VERSION "Generated from CSV"

NS_ :

BS_:

BU_: CAN_IO CAR_PC EL_ECU PANTHER PUMA_FL PUMA_FR PUMA_R1 PUMA_R2 PUMA_RR1 SIMI
VAL_TABLE_ VT_SEAL_ActivationStatus 2 "deflate" 1 "inflate" 0 "ready" ;
VAL_TABLE_ VT_MON_State 1 "available" 0 "not available" ;
VAL_TABLE_ VT_HMI_SensorFusionRequest 1 "requested" 0 "not requested" ;
VAL_TABLE_ VT_ECU_PowerRequest 1 "Shutdown" 0 "Power On (default)" ;
VAL_TABLE_ VT_HMI_SEALActivationRequest 1 "request for inflate" 0 "request for exflate (default)" ;
VAL_TABLE_ VT_ELK_ResetErrorFlags 1 "reset error counters" 0 "nothing" ;
VAL_TABLE_ VT_ELK_LockingStatus 1 "locked" 0 "unlocked" ;
VAL_TABLE_ VT_ELK_LockingRequest 1 "Request for lock" 0 "No lock" ;
VAL_TABLE_ VT_ELK_ActuatorStatus 2 "Failure detected" 1 "Failure in previous cycle" 0 "No failure" ;
VAL_TABLE_ VT_BSW_BuckleState 1 "Buckled" 0 "Unbuckled" ;

BO_ 3221225472 VECTOR__INDEPENDENT_SIG_MSG: 0 Vector__XXX
 SG_ Generic_SeatFunctionEnable : 0|5@1+ (1,0) [0|31] "" Vector__XXX
 SG_ HB_State_FL : 0|8@1+ (1,0) [0|255] "" Vector__XXX

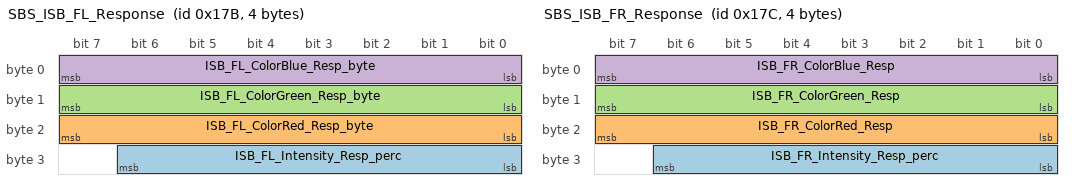
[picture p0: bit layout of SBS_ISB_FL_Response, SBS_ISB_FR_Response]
BO_ 379 SBS_ISB_FL_Response: 4 PUMA_FL
 SG_ ISB_FL_Intensity_Resp_perc : 24|7@1+ (1,0) [0|127] "" Vector__XXX
 SG_ ISB_FL_ColorRed_Resp_byte : 16|8@1+ (1,0) [0|255] "" Vector__XXX
 SG_ ISB_FL_ColorGreen_Resp_byte : 8|8@1+ (1,0) [0|255] "" Vector__XXX
 SG_ ISB_FL_ColorBlue_Resp_byte : 0|8@1+ (1,0) [0|255] "" Vector__XXX

BO_ 380 SBS_ISB_FR_Response: 4 PUMA_FR
 SG_ ISB_FR_Intensity_Resp_perc : 24|7@1+ (1,0) [0|127] "" Vector__XXX
 SG_ ISB_FR_ColorRed_Resp : 16|8@1+ (1,0) [0|255] "" Vector__XXX
 SG_ ISB_FR_ColorGreen_Resp : 8|8@1+ (1,0) [0|255] "" Vector__XXX
 SG_ ISB_FR_ColorBlue_Resp : 0|8@1+ (1,0) [0|255] "" Vector__XXX

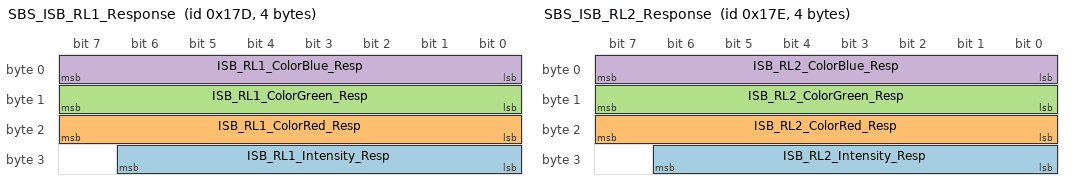
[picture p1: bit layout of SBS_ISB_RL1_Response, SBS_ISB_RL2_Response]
BO_ 381 SBS_ISB_RL1_Response: 4 PUMA_R1
 SG_ ISB_RL1_Intensity_Resp : 24|7@1+ (1,0) [0|127] "" Vector__XXX
 SG_ ISB_RL1_ColorRed_Resp : 16|8@1+ (1,0) [0|255] "" Vector__XXX
 SG_ ISB_RL1_ColorGreen_Resp : 8|8@1+ (1,0) [0|255] "" Vector__XXX
 SG_ ISB_RL1_ColorBlue_Resp : 0|8@1+ (1,0) [0|255] "" Vector__XXX

BO_ 382 SBS_ISB_RL2_Response: 4 PUMA_R2
 SG_ ISB_RL2_Intensity_Resp : 24|7@1+ (1,0) [0|127] "" Vector__XXX
 SG_ ISB_RL2_ColorRed_Resp : 16|8@1+ (1,0) [0|255] "" Vector__XXX
 SG_ ISB_RL2_ColorGreen_Resp : 8|8@1+ (1,0) [0|255] "" Vector__XXX
 SG_ ISB_RL2_ColorBlue_Resp : 0|8@1+ (1,0) [0|255] "" Vector__XXX

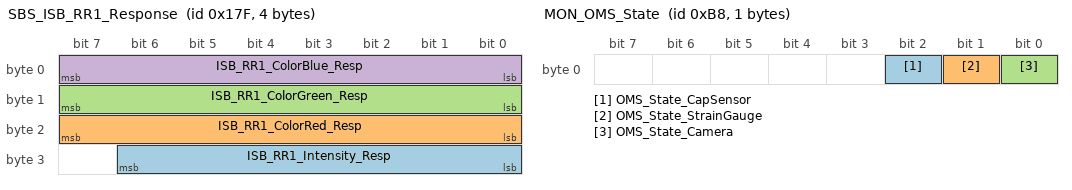
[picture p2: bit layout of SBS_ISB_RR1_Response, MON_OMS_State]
BO_ 383 SBS_ISB_RR1_Response: 4 PUMA_RR1
 SG_ ISB_RR1_Intensity_Resp : 24|7@1+ (1,0) [0|127] "" Vector__XXX
 SG_ ISB_RR1_ColorRed_Resp : 16|8@1+ (1,0) [0|255] "" Vector__XXX
 SG_ ISB_RR1_ColorGreen_Resp : 8|8@1+ (1,0) [0|255] "" Vector__XXX
 SG_ ISB_RR1_ColorBlue_Resp : 0|8@1+ (1,0) [0|255] "" Vector__XXX

BO_ 371 IRS_SEAL_RL2_Response: 1 PANTHER
 SG_ SEAL_RL2_ActivationStatus : 0|2@1+ (1,0) [0|3] "" Vector__XXX

BO_ 414 SBS_HB_RR1_Response: 4 PUMA_RR1
 SG_ HB_TargetTemp_RR1 : 24|8@1+ (0.5,-40) [-40|87.5] "" Vector__XXX
 SG_ HB_State_RR1 : 8|8@1+ (1,0) [0|255] "" Vector__XXX
 SG_ HB_ActualTemp_RR1 : 16|8@1+ (0.5,-40) [-40|87.5] "" Vector__XXX
 SG_ HB_PowerOut_RR1 : 0|8@1+ (1,0) [0|255] "" Vector__XXX

BO_ 413 SBS_HB_RL2_Response: 4 PUMA_R2
 SG_ HB_TargetTemp_RL2 : 24|8@1+ (0.5,-40) [-40|87.5] "" Vector__XXX
 SG_ HB_State_RL2 : 8|8@1+ (1,0) [0|255] "" Vector__XXX
 SG_ HB_ActualTemp_RL2 : 16|8@1+ (0.5,-40) [-40|87.5] "" Vector__XXX
 SG_ HB_PowerOut_RL2 : 0|8@1+ (1,0) [0|255] "" Vector__XXX

BO_ 412 SBS_HB_RL1_Response: 4 PUMA_R1
 SG_ HB_TargetTemp_RL1 : 24|8@1+ (0.5,-40) [-40|87.5] "" Vector__XXX
 SG_ HB_State_RL1 : 8|8@1+ (1,0) [0|255] "" Vector__XXX
 SG_ HB_ActualTemp_RL1 : 16|8@1+ (0.5,-40) [-40|87.5] "" Vector__XXX
 SG_ HB_PowerOut_RL1 : 0|8@1+ (1,0) [0|255] "" Vector__XXX

BO_ 184 MON_OMS_State: 1 SIMI
 SG_ OMS_State_CapSensor : 2|1@1+ (1,0) [0|1] "" Vector__XXX
 SG_ OMS_State_StrainGauge : 1|1@1+ (1,0) [0|1] "" Vector__XXX
 SG_ OMS_State_Camera : 0|1@1+ (1,0) [0|1] "" Vector__XXX

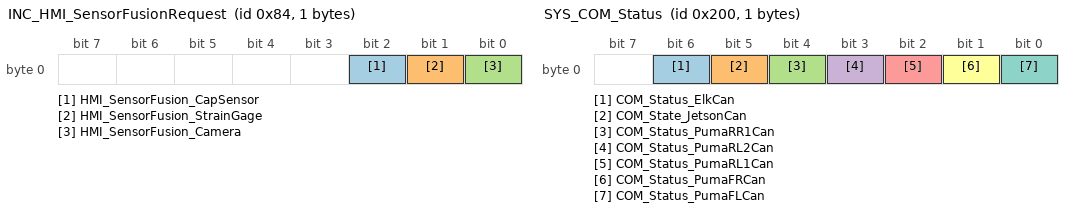
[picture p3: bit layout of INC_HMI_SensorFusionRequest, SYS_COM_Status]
BO_ 132 INC_HMI_SensorFusionRequest: 1 CAR_PC
 SG_ HMI_SensorFusion_CapSensor : 2|1@1+ (1,0) [0|1] "" Vector__XXX
 SG_ HMI_SensorFusion_StrainGage : 1|1@1+ (1,0) [0|1] "" Vector__XXX
 SG_ HMI_SensorFusion_Camera : 0|1@1+ (1,0) [0|1] "" Vector__XXX

BO_ 513 SYS_ECU_PowerRequest: 1 CAN_IO
 SG_ ECU_PowerRequest_Jetson : 0|1@1+ (1,0) [0|1] "" Vector__XXX

BO_ 512 SYS_COM_Status: 1 PANTHER
 SG_ COM_Status_ElkCan : 6|1@1+ (1,0) [0|1] "" Vector__XXX
 SG_ COM_State_JetsonCan : 5|1@1+ (1,0) [0|1] "" Vector__XXX
 SG_ COM_Status_PumaRR1Can : 4|1@1+ (1,0) [0|1] "" Vector__XXX
 SG_ COM_Status_PumaRL2Can : 3|1@1+ (1,0) [0|1] "" Vector__XXX
 SG_ COM_Status_PumaRL1Can : 2|1@1+ (1,0) [0|1] "" Vector__XXX
 SG_ COM_Status_PumaFRCan : 1|1@1+ (1,0) [0|1] "" Vector__XXX
 SG_ COM_Status_PumaFLCan : 0|1@1+ (1,0) [0|1] "" Vector__XXX

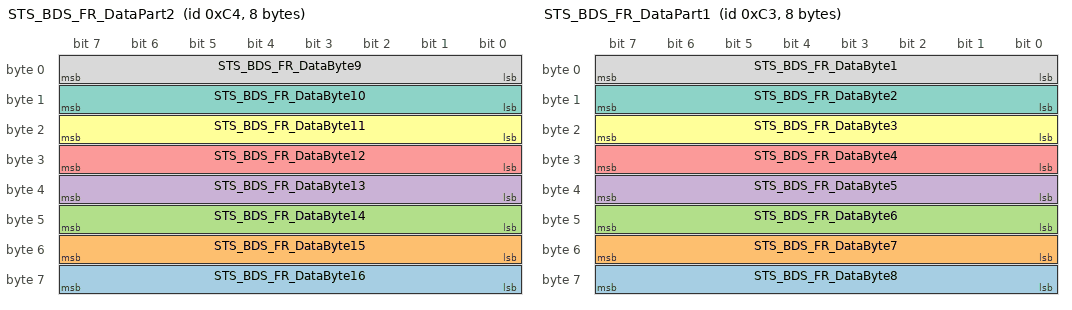
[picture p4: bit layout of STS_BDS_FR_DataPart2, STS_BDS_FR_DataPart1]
BO_ 196 STS_BDS_FR_DataPart2: 8 Vector__XXX
 SG_ STS_BDS_FR_DataByte16 : 56|8@1+ (1,0) [0|255] "" Vector__XXX
 SG_ STS_BDS_FR_DataByte15 : 48|8@1+ (1,0) [0|255] "" Vector__XXX
 SG_ STS_BDS_FR_DataByte14 : 40|8@1+ (1,0) [0|255] "" Vector__XXX
 SG_ STS_BDS_FR_DataByte13 : 32|8@1+ (1,0) [0|255] "" Vector__XXX
 SG_ STS_BDS_FR_DataByte12 : 24|8@1+ (1,0) [0|255] "" Vector__XXX
 SG_ STS_BDS_FR_DataByte11 : 16|8@1+ (1,0) [0|255] "" Vector__XXX
 SG_ STS_BDS_FR_DataByte10 : 8|8@1+ (1,0) [0|255] "" Vector__XXX
 SG_ STS_BDS_FR_DataByte9 : 0|8@1+ (1,0) [0|255] "" Vector__XXX

BO_ 195 STS_BDS_FR_DataPart1: 8 Vector__XXX
 SG_ STS_BDS_FR_DataByte8 : 56|8@1+ (1,0) [0|255] "" Vector__XXX
 SG_ STS_BDS_FR_DataByte7 : 48|8@1+ (1,0) [0|255] "" Vector__XXX
 SG_ STS_BDS_FR_DataByte6 : 40|8@1+ (1,0) [0|255] "" Vector__XXX
 SG_ STS_BDS_FR_DataByte5 : 32|8@1+ (1,0) [0|255] "" Vector__XXX
 SG_ STS_BDS_FR_DataByte4 : 24|8@1+ (1,0) [0|255] "" Vector__XXX
 SG_ STS_BDS_FR_DataByte3 : 16|8@1+ (1,0) [0|255] "" Vector__XXX
 SG_ STS_BDS_FR_DataByte2 : 8|8@1+ (1,0) [0|255] "" Vector__XXX
 SG_ STS_BDS_FR_DataByte1 : 0|8@1+ (1,0) [0|255] "" Vector__XXX

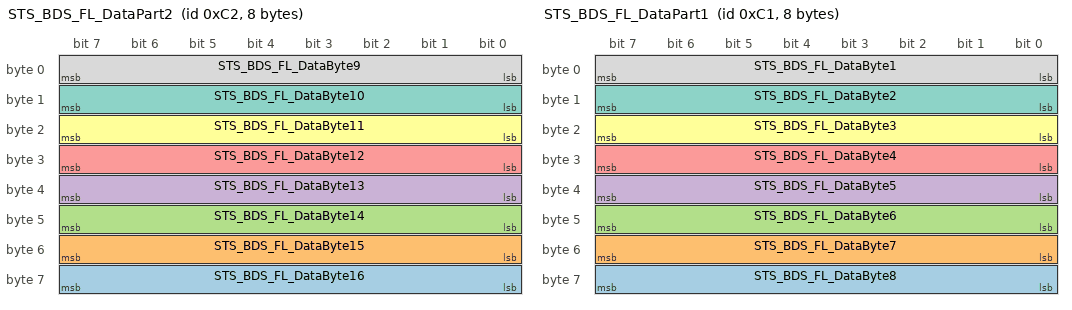
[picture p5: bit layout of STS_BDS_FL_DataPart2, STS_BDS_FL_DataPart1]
BO_ 194 STS_BDS_FL_DataPart2: 8 Vector__XXX
 SG_ STS_BDS_FL_DataByte16 : 56|8@1+ (1,0) [0|255] "" Vector__XXX
 SG_ STS_BDS_FL_DataByte15 : 48|8@1+ (1,0) [0|255] "" Vector__XXX
 SG_ STS_BDS_FL_DataByte14 : 40|8@1+ (1,0) [0|255] "" Vector__XXX
 SG_ STS_BDS_FL_DataByte13 : 32|8@1+ (1,0) [0|255] "" Vector__XXX
 SG_ STS_BDS_FL_DataByte12 : 24|8@1+ (1,0) [0|255] "" Vector__XXX
 SG_ STS_BDS_FL_DataByte11 : 16|8@1+ (1,0) [0|255] "" Vector__XXX
 SG_ STS_BDS_FL_DataByte10 : 8|8@1+ (1,0) [0|255] "" Vector__XXX
 SG_ STS_BDS_FL_DataByte9 : 0|8@1+ (1,0) [0|255] "" Vector__XXX

BO_ 193 STS_BDS_FL_DataPart1: 8 Vector__XXX
 SG_ STS_BDS_FL_DataByte8 : 56|8@1+ (1,0) [0|255] "" Vector__XXX
 SG_ STS_BDS_FL_DataByte7 : 48|8@1+ (1,0) [0|255] "" Vector__XXX
 SG_ STS_BDS_FL_DataByte6 : 40|8@1+ (1,0) [0|255] "" Vector__XXX
 SG_ STS_BDS_FL_DataByte5 : 32|8@1+ (1,0) [0|255] "" Vector__XXX
 SG_ STS_BDS_FL_DataByte4 : 24|8@1+ (1,0) [0|255] "" Vector__XXX
 SG_ STS_BDS_FL_DataByte3 : 16|8@1+ (1,0) [0|255] "" Vector__XXX
 SG_ STS_BDS_FL_DataByte2 : 8|8@1+ (1,0) [0|255] "" Vector__XXX
 SG_ STS_BDS_FL_DataByte1 : 0|8@1+ (1,0) [0|255] "" Vector__XXX

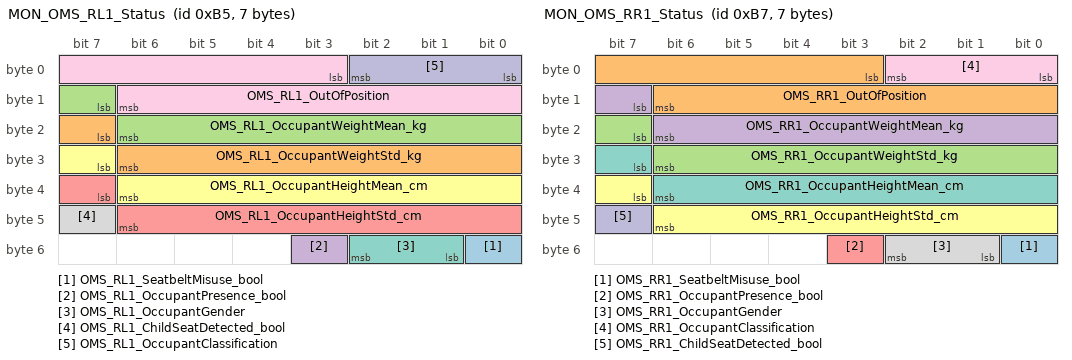
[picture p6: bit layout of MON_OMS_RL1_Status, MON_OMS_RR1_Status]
BO_ 181 MON_OMS_RL1_Status: 7 Vector__XXX
 SG_ OMS_RL1_SeatbeltMisuse_bool : 48|1@1+ (1,0) [0|1] "" Vector__XXX
 SG_ OMS_RL1_OccupantWeightStd_kg : 23|8@1+ (1,0) [0|255] "" Vector__XXX
 SG_ OMS_RL1_OccupantWeightMean_kg : 15|8@1+ (1,0) [0|255] "" Vector__XXX
 SG_ OMS_RL1_OccupantPresence_bool : 51|1@1+ (1,0) [0|1] "" Vector__XXX
 SG_ OMS_RL1_OccupantHeightStd_cm : 39|8@1+ (1,0) [0|255] "" Vector__XXX
 SG_ OMS_RL1_OccupantHeightMean_cm : 31|8@1+ (1,0) [0|255] "" Vector__XXX
 SG_ OMS_RL1_OccupantGender : 49|2@1+ (1,0) [0|3] "" Vector__XXX
 SG_ OMS_RL1_ChildSeatDetected_bool : 47|1@1+ (1,0) [0|1] "" Vector__XXX
 SG_ OMS_RL1_OutOfPosition : 3|12@1+ (1,0) [0|4095] "" Vector__XXX
 SG_ OMS_RL1_OccupantClassification : 0|3@1+ (1,0) [0|7] "" Vector__XXX

BO_ 183 MON_OMS_RR1_Status: 7 Vector__XXX
 SG_ OMS_RR1_SeatbeltMisuse_bool : 48|1@1+ (1,0) [0|1] "" Vector__XXX
 SG_ OMS_RR1_OutOfPosition : 3|12@1+ (1,0) [0|4095] "" Vector__XXX
 SG_ OMS_RR1_OccupantWeightStd_kg : 23|8@1+ (1,0) [0|255] "" Vector__XXX
 SG_ OMS_RR1_OccupantWeightMean_kg : 15|8@1+ (1,0) [0|255] "" Vector__XXX
 SG_ OMS_RR1_OccupantPresence_bool : 51|1@1+ (1,0) [0|1] "" Vector__XXX
 SG_ OMS_RR1_OccupantHeightStd_cm : 39|8@1+ (1,0) [0|255] "" Vector__XXX
 SG_ OMS_RR1_OccupantHeightMean_cm : 31|8@1+ (1,0) [0|255] "" Vector__XXX
 SG_ OMS_RR1_OccupantGender : 49|2@1+ (1,0) [0|3] "" Vector__XXX
 SG_ OMS_RR1_OccupantClassification : 0|3@1+ (1,0) [0|7] "" Vector__XXX
 SG_ OMS_RR1_ChildSeatDetected_bool : 47|1@1+ (1,0) [0|1] "" Vector__XXX

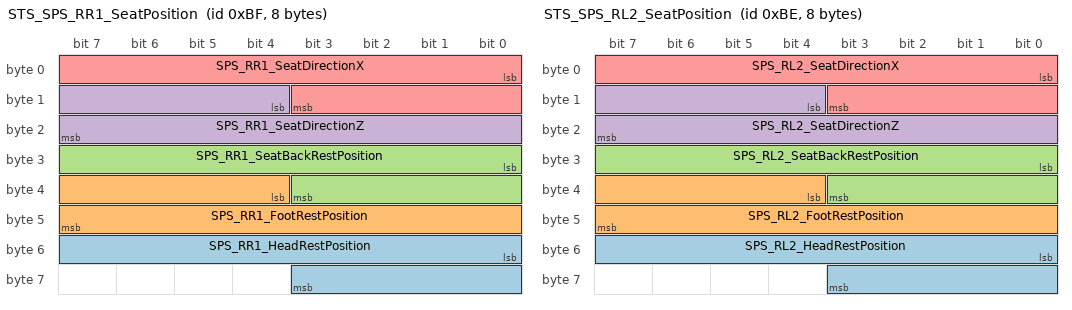
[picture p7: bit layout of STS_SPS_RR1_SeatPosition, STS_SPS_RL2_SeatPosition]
BO_ 191 STS_SPS_RR1_SeatPosition: 8 Vector__XXX
 SG_ SPS_RR1_HeadRestPosition : 48|12@1+ (1,0) [0|4095] "" Vector__XXX
 SG_ SPS_RR1_FootRestPosition : 36|12@1+ (1,0) [0|4095] "" Vector__XXX
 SG_ SPS_RR1_SeatBackRestPosition : 24|12@1+ (1,0) [0|4095] "" Vector__XXX
 SG_ SPS_RR1_SeatDirectionZ : 12|12@1+ (1,0) [0|4095] "" Vector__XXX
 SG_ SPS_RR1_SeatDirectionX : 0|12@1+ (1,0) [0|4095] "" Vector__XXX

BO_ 190 STS_SPS_RL2_SeatPosition: 8 Vector__XXX
 SG_ SPS_RL2_HeadRestPosition : 48|12@1+ (1,0) [0|4095] "" Vector__XXX
 SG_ SPS_RL2_FootRestPosition : 36|12@1+ (1,0) [0|4095] "" Vector__XXX
 SG_ SPS_RL2_SeatBackRestPosition : 24|12@1+ (1,0) [0|4095] "" Vector__XXX
 SG_ SPS_RL2_SeatDirectionZ : 12|12@1+ (1,0) [0|4095] "" Vector__XXX
 SG_ SPS_RL2_SeatDirectionX : 0|12@1+ (1,0) [0|4095] "" Vector__XXX

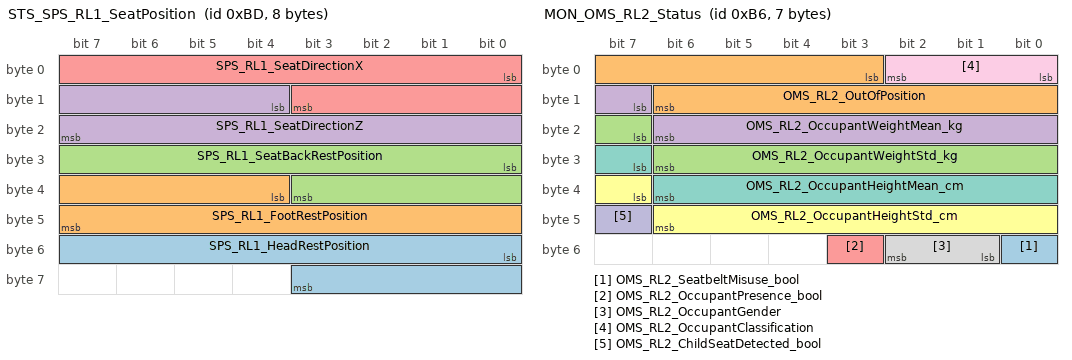
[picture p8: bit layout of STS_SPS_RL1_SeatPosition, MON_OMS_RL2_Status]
BO_ 189 STS_SPS_RL1_SeatPosition: 8 Vector__XXX
 SG_ SPS_RL1_HeadRestPosition : 48|12@1+ (1,0) [0|4095] "" Vector__XXX
 SG_ SPS_RL1_FootRestPosition : 36|12@1+ (1,0) [0|4095] "" Vector__XXX
 SG_ SPS_RL1_SeatBackRestPosition : 24|12@1+ (1,0) [0|4095] "" Vector__XXX
 SG_ SPS_RL1_SeatDirectionZ : 12|12@1+ (1,0) [0|4095] "" Vector__XXX
 SG_ SPS_RL1_SeatDirectionX : 0|12@1+ (1,0) [0|4095] "" Vector__XXX

BO_ 182 MON_OMS_RL2_Status: 7 Vector__XXX
 SG_ OMS_RL2_SeatbeltMisuse_bool : 48|1@1+ (1,0) [0|1] "" Vector__XXX
 SG_ OMS_RL2_OutOfPosition : 3|12@1+ (1,0) [0|4095] "" Vector__XXX
 SG_ OMS_RL2_OccupantWeightStd_kg : 23|8@1+ (1,0) [0|255] "" Vector__XXX
 SG_ OMS_RL2_OccupantWeightMean_kg : 15|8@1+ (1,0) [0|255] "" Vector__XXX
 SG_ OMS_RL2_OccupantPresence_bool : 51|1@1+ (1,0) [0|1] "" Vector__XXX
 SG_ OMS_RL2_OccupantHeightStd_cm : 39|8@1+ (1,0) [0|255] "" Vector__XXX
 SG_ OMS_RL2_OccupantHeightMean_cm : 31|8@1+ (1,0) [0|255] "" Vector__XXX
 SG_ OMS_RL2_OccupantGender : 49|2@1+ (1,0) [0|3] "" Vector__XXX
 SG_ OMS_RL2_OccupantClassification : 0|3@1+ (1,0) [0|7] "" Vector__XXX
 SG_ OMS_RL2_ChildSeatDetected_bool : 47|1@1+ (1,0) [0|1] "" Vector__XXX

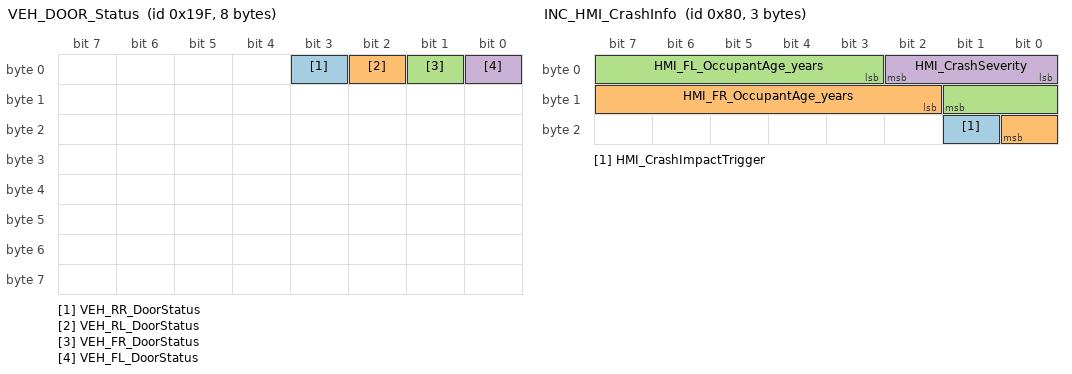
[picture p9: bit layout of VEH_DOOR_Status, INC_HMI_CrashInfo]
BO_ 415 VEH_DOOR_Status: 8 Vector__XXX
 SG_ VEH_RR_DoorStatus : 3|1@1+ (1,0) [0|1] "" Vector__XXX
 SG_ VEH_RL_DoorStatus : 2|1@1+ (1,0) [0|1] "" Vector__XXX
 SG_ VEH_FR_DoorStatus : 1|1@1+ (1,0) [0|1] "" Vector__XXX
 SG_ VEH_FL_DoorStatus : 0|1@1+ (1,0) [0|1] "" Vector__XXX

BO_ 128 INC_HMI_CrashInfo: 3 CAR_PC
 SG_ HMI_CrashImpactTrigger : 17|1@1+ (1,0) [0|1] ""  PANTHER
 SG_ HMI_FR_OccupantAge_years : 10|7@1+ (1,0) [0|127] ""  PANTHER
 SG_ HMI_FL_OccupantAge_years : 3|7@1+ (1,0) [0|127] ""  PANTHER
 SG_ HMI_CrashSeverity : 0|3@1+ (1,0) [0|7] ""  PANTHER

BO_ 129 INC_HMI_SEALRequest: 1 CAR_PC
 SG_ HMI_SEAL_ActivationRequest : 0|2@1+ (1,0) [0|3] ""  PANTHER

BO_ 177 MON_ARS_InjuryRisk: 4 PANTHER
 SG_ ARS_FR_InjuryRiskNonAdaptive : 24|8@1+ (1,0) [0|255] ""  CAR_PC
 SG_ ARS_FR_InjuryRiskAdaptive : 16|8@1+ (1,0) [0|255] ""  CAR_PC
 SG_ ARS_FL_InjuryRiskNonAdaptive : 8|8@1+ (1,0) [0|255] ""  CAR_PC
 SG_ ARS_FL_InjuryRiskAdaptive : 0|8@1+ (1,0) [0|255] ""  CAR_PC

BO_ 130 MON_ARS_MSLLRequest: 1 PANTHER
 SG_ ARS_MSLL_ActivationRequest : 0|8@1+ (1,0) [0|255] ""  CAR_PC

BO_ 178 MON_ARS_TTF: 4 PANTHER
 SG_ ARS_FR_TimeToFireSeatbelt : 24|8@1+ (1,0) [0|255] ""  CAR_PC
 SG_ ARS_FR_TimeToFireAirbag : 16|8@1+ (1,0) [0|255] ""  CAR_PC
 SG_ ARS_FL_TimeToFireSeatbelt : 8|8@1+ (1,0) [0|255] ""  CAR_PC
 SG_ ARS_FL_TimeToFireAirbag : 0|8@1+ (1,0) [0|255] ""  CAR_PC

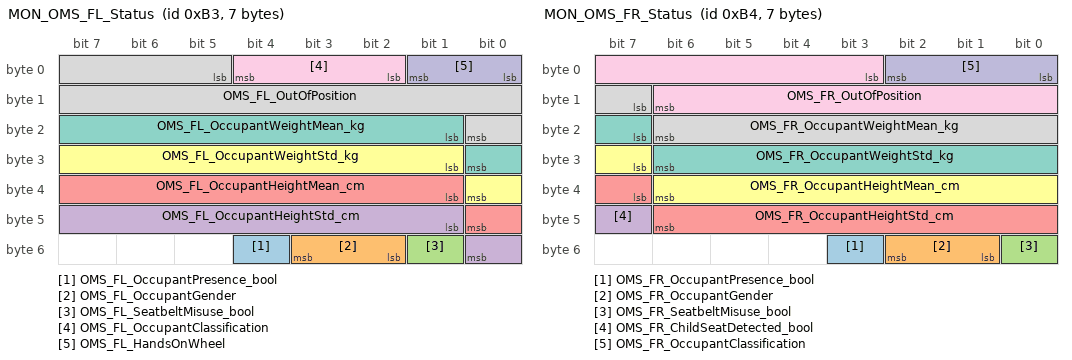
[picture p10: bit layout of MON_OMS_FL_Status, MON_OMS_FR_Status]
BO_ 179 MON_OMS_FL_Status: 7 PANTHER
 SG_ OMS_FL_OccupantPresence_bool : 52|1@1+ (1,0) [0|1] "" Vector__XXX
 SG_ OMS_FL_OccupantGender : 50|2@1+ (1,0) [0|3] ""  CAR_PC,PANTHER
 SG_ OMS_FL_SeatbeltMisuse_bool : 49|1@1+ (1,0) [0|1] ""  CAR_PC,PANTHER
 SG_ OMS_FL_OccupantHeightStd_cm : 41|8@1+ (1,0) [0|255] ""  CAR_PC,PANTHER
 SG_ OMS_FL_OccupantHeightMean_cm : 33|8@1+ (1,0) [0|255] ""  CAR_PC,PANTHER
 SG_ OMS_FL_OccupantWeightStd_kg : 25|8@1+ (1,0) [0|255] ""  CAR_PC,PANTHER
 SG_ OMS_FL_OccupantWeightMean_kg : 17|8@1+ (1,0) [0|255] ""  CAR_PC,PANTHER
 SG_ OMS_FL_OutOfPosition : 5|12@1+ (1,0) [0|4095] ""  PANTHER
 SG_ OMS_FL_OccupantClassification : 2|3@1+ (1,0) [0|7] ""  CAR_PC,PANTHER
 SG_ OMS_FL_HandsOnWheel : 0|2@1+ (1,0) [0|3] ""  CAR_PC,PANTHER

BO_ 180 MON_OMS_FR_Status: 7 PANTHER
 SG_ OMS_FR_OccupantPresence_bool : 51|1@1+ (1,0) [0|1] "" Vector__XXX
 SG_ OMS_FR_OccupantGender : 49|2@1+ (1,0) [0|3] ""  CAR_PC,PANTHER
 SG_ OMS_FR_SeatbeltMisuse_bool : 48|1@1+ (1,0) [0|1] ""  CAR_PC,PANTHER
 SG_ OMS_FR_ChildSeatDetected_bool : 47|1@1+ (1,0) [0|1] ""  CAR_PC,PANTHER
 SG_ OMS_FR_OccupantHeightStd_cm : 39|8@1+ (1,0) [0|255] ""  CAR_PC,PANTHER
 SG_ OMS_FR_OccupantHeightMean_cm : 31|8@1+ (1,0) [0|255] ""  CAR_PC,PANTHER
 SG_ OMS_FR_OccupantWeightStd_kg : 23|8@1+ (1,0) [0|255] ""  CAR_PC,PANTHER
 SG_ OMS_FR_OccupantWeightMean_kg : 15|8@1+ (1,0) [0|255] ""  CAR_PC,PANTHER
 SG_ OMS_FR_OutOfPosition : 3|12@1+ (1,0) [0|4095] ""  PANTHER
 SG_ OMS_FR_OccupantClassification : 0|3@1+ (1,0) [0|7] ""  CAR_PC,PANTHER

BO_ 176 MON_SMA_VehicleState: 1 PANTHER
 SG_ SMA_VehicleStable : 0|1@1+ (1,0) [0|1] ""  CAR_PC

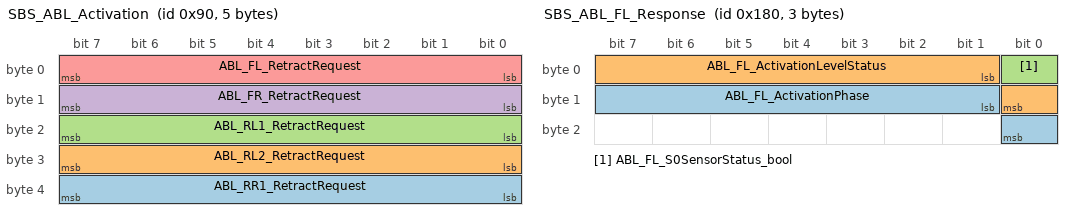
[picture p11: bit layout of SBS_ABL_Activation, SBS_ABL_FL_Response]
BO_ 144 SBS_ABL_Activation: 5 PANTHER
 SG_ ABL_RR1_RetractRequest : 32|8@1+ (1,0) [0|255] ""  PANTHER,PUMA_RR1
 SG_ ABL_RL2_RetractRequest : 24|8@1+ (1,0) [0|255] ""  PANTHER,PUMA_R2
 SG_ ABL_RL1_RetractRequest : 16|8@1+ (1,0) [0|255] ""  PANTHER,PUMA_R1
 SG_ ABL_FR_RetractRequest : 8|8@1+ (1,0) [0|255] ""  PANTHER,PUMA_FR
 SG_ ABL_FL_RetractRequest : 0|8@1+ (1,0) [0|255] ""  PANTHER,PUMA_FL

BO_ 384 SBS_ABL_FL_Response: 3 PUMA_FL
 SG_ ABL_FL_ActivationPhase : 9|8@1+ (1,0) [0|255] ""  PANTHER
 SG_ ABL_FL_ActivationLevelStatus : 1|8@1+ (1,0) [0|255] ""  PANTHER
 SG_ ABL_FL_S0SensorStatus_bool : 0|1@1+ (1,0) [0|1] ""  PANTHER

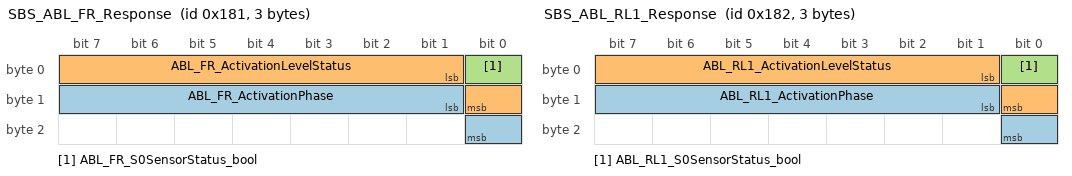
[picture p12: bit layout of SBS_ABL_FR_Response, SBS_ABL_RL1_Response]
BO_ 385 SBS_ABL_FR_Response: 3 PUMA_FR
 SG_ ABL_FR_ActivationPhase : 9|8@1+ (1,0) [0|255] ""  PANTHER
 SG_ ABL_FR_ActivationLevelStatus : 1|8@1+ (1,0) [0|255] ""  PANTHER
 SG_ ABL_FR_S0SensorStatus_bool : 0|1@1+ (1,0) [0|1] ""  PANTHER

BO_ 386 SBS_ABL_RL1_Response: 3 PUMA_R1
 SG_ ABL_RL1_ActivationPhase : 9|8@1+ (1,0) [0|255] ""  PANTHER
 SG_ ABL_RL1_ActivationLevelStatus : 1|8@1+ (1,0) [0|255] ""  PANTHER
 SG_ ABL_RL1_S0SensorStatus_bool : 0|1@1+ (1,0) [0|1] ""  PANTHER

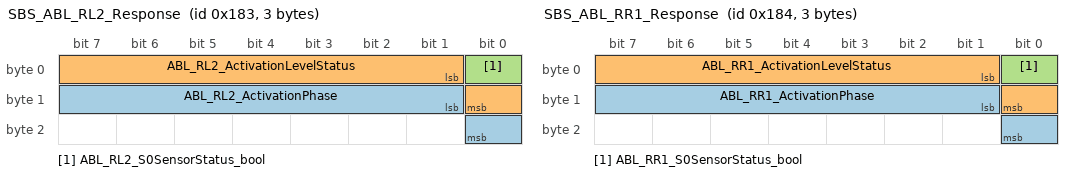
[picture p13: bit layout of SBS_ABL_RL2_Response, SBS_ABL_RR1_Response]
BO_ 387 SBS_ABL_RL2_Response: 3 PUMA_R2
 SG_ ABL_RL2_ActivationPhase : 9|8@1+ (1,0) [0|255] ""  PANTHER
 SG_ ABL_RL2_ActivationLevelStatus : 1|8@1+ (1,0) [0|255] ""  PANTHER
 SG_ ABL_RL2_S0SensorStatus_bool : 0|1@1+ (1,0) [0|1] ""  PANTHER

BO_ 388 SBS_ABL_RR1_Response: 3 PUMA_RR1
 SG_ ABL_RR1_ActivationPhase : 9|8@1+ (1,0) [0|255] ""  PANTHER
 SG_ ABL_RR1_ActivationLevelStatus : 1|8@1+ (1,0) [0|255] ""  PANTHER
 SG_ ABL_RR1_S0SensorStatus_bool : 0|1@1+ (1,0) [0|1] ""  PANTHER

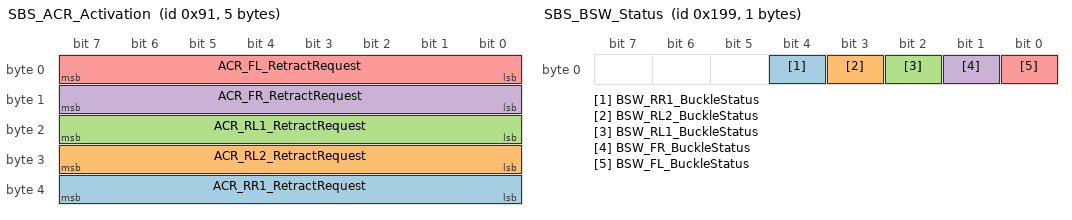
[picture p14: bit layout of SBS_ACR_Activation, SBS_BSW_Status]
BO_ 145 SBS_ACR_Activation: 5 PANTHER
 SG_ ACR_RR1_RetractRequest : 32|8@1+ (1,0) [0|255] ""  PANTHER,PUMA_RR1
 SG_ ACR_RL2_RetractRequest : 24|8@1+ (1,0) [0|255] ""  PANTHER,PUMA_R2
 SG_ ACR_RL1_RetractRequest : 16|8@1+ (1,0) [0|255] ""  PANTHER,PUMA_R1
 SG_ ACR_FR_RetractRequest : 8|8@1+ (1,0) [0|255] ""  PANTHER,PUMA_FR
 SG_ ACR_FL_RetractRequest : 0|8@1+ (1,0) [0|255] ""  PANTHER,PUMA_FL

BO_ 392 SBS_ACR_FL_Response: 3 PUMA_FL
 SG_ ACR_FL_SpoolFasterClutch : 16|8@1+ (1,0) [0|255] ""  PANTHER
 SG_ ACR_FL_ActivationPhase : 8|8@1+ (1,0) [0|255] ""  PANTHER
 SG_ ACR_FL_ActivationLevelStatus : 0|8@1+ (1,0) [0|255] ""  PANTHER

BO_ 393 SBS_ACR_FR_Response: 3 PUMA_FR
 SG_ ACR_FR_SpoolFasterClutch : 16|8@1+ (1,0) [0|255] ""  PANTHER
 SG_ ACR_FR_ActivationPhase : 8|8@1+ (1,0) [0|255] ""  PANTHER
 SG_ ACR_FR_ActivationLevelStatus : 0|8@1+ (1,0) [0|255] ""  PANTHER

BO_ 394 SBS_ACR_RL1_Response: 3 PUMA_R1
 SG_ ACR_RL1_SpoolFasterClutch : 16|8@1+ (1,0) [0|255] ""  PANTHER
 SG_ ACR_RL1_ActivationPhase : 8|8@1+ (1,0) [0|255] ""  PANTHER
 SG_ ACR_RL1_ActivationLevelStatus : 0|8@1+ (1,0) [0|255] ""  PANTHER

BO_ 395 SBS_ACR_RL2_Response: 3 PUMA_R2
 SG_ ACR_RL2_SpoolFasterClutch : 16|8@1+ (1,0) [0|255] ""  PANTHER
 SG_ ACR_RL2_ActivationPhase : 8|8@1+ (1,0) [0|255] ""  PANTHER
 SG_ ACR_RL2_ActivationLevelStatus : 0|8@1+ (1,0) [0|255] ""  PANTHER

BO_ 396 SBS_ACR_RR1_Response: 3 PUMA_RR1
 SG_ ACR_RR1_SpoolFasterClutch : 16|8@1+ (1,0) [0|255] ""  PANTHER
 SG_ ACR_RR1_ActivationPhase : 8|8@1+ (1,0) [0|255] ""  PANTHER
 SG_ ACR_RR1_ActivationLevelStatus : 0|8@1+ (1,0) [0|255] ""  PANTHER

BO_ 409 SBS_BSW_Status: 1 PANTHER
 SG_ BSW_RR1_BuckleStatus : 4|1@1+ (1,0) [0|1] ""  CAR_PC
 SG_ BSW_RL2_BuckleStatus : 3|1@1+ (1,0) [0|1] ""  CAR_PC
 SG_ BSW_RL1_BuckleStatus : 2|1@1+ (1,0) [0|1] ""  CAR_PC
 SG_ BSW_FR_BuckleStatus : 1|1@1+ (1,0) [0|1] ""  CAR_PC
 SG_ BSW_FL_BuckleStatus : 0|1@1+ (1,0) [0|1] ""  CAR_PC

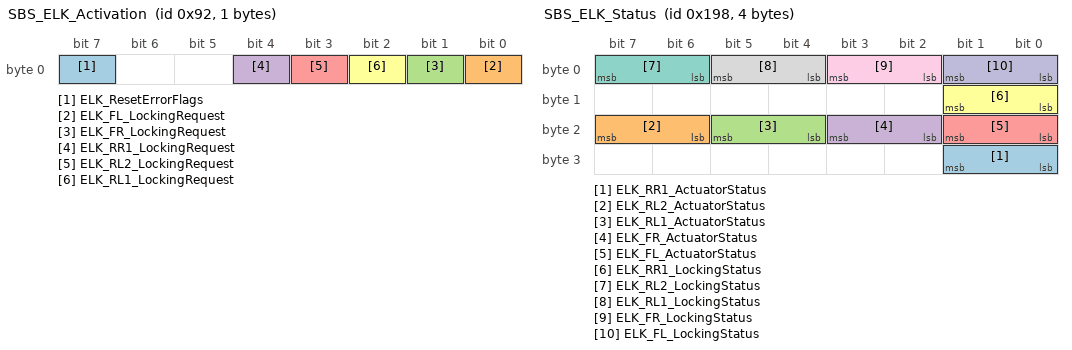
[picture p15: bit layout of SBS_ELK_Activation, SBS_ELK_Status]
BO_ 146 SBS_ELK_Activation: 1 PANTHER
 SG_ ELK_ResetErrorFlags : 7|1@1+ (1,0) [0|1] "" Vector__XXX
 SG_ ELK_FL_LockingRequest : 0|1@1+ (1,0) [0|1] ""  EL_ECU,PANTHER
 SG_ ELK_FR_LockingRequest : 1|1@1+ (1,0) [0|1] ""  EL_ECU,PANTHER
 SG_ ELK_RR1_LockingRequest : 4|1@1+ (1,0) [0|1] ""  PANTHER,EL_ECU
 SG_ ELK_RL2_LockingRequest : 3|1@1+ (1,0) [0|1] ""  PANTHER,EL_ECU
 SG_ ELK_RL1_LockingRequest : 2|1@1+ (1,0) [0|1] ""  PANTHER,EL_ECU

BO_ 408 SBS_ELK_Status: 4 PANTHER
 SG_ ELK_RR1_ActuatorStatus : 24|2@1+ (1,0) [0|3] "" Vector__XXX
 SG_ ELK_RL2_ActuatorStatus : 22|2@1+ (1,0) [0|3] "" Vector__XXX
 SG_ ELK_RL1_ActuatorStatus : 20|2@1+ (1,0) [0|3] "" Vector__XXX
 SG_ ELK_FR_ActuatorStatus : 18|2@1+ (1,0) [0|3] "" Vector__XXX
 SG_ ELK_FL_ActuatorStatus : 16|2@1+ (1,0) [0|3] "" Vector__XXX
 SG_ ELK_RR1_LockingStatus : 8|2@1+ (1,0) [0|3] ""  CAR_PC,PANTHER
 SG_ ELK_RL2_LockingStatus : 6|2@1+ (1,0) [0|3] ""  CAR_PC,PANTHER
 SG_ ELK_RL1_LockingStatus : 4|2@1+ (1,0) [0|3] ""  CAR_PC,PANTHER
 SG_ ELK_FR_LockingStatus : 2|2@1+ (1,0) [0|3] ""  CAR_PC,PANTHER
 SG_ ELK_FL_LockingStatus : 0|2@1+ (1,0) [0|3] ""  CAR_PC,PANTHER

BO_ 411 SBS_HB_FR_Response: 4 PUMA_FR
 SG_ HB_TargetTemp_FR : 16|8@1+ (0.5,-40) [-40|87.5] "" Vector__XXX
 SG_ HB_State_FR : 24|8@1+ (1,0) [0|255] "" Vector__XXX
 SG_ HB_ActualTemp_FR : 8|8@1+ (0.5,-40) [-40|87.5] "" Vector__XXX
 SG_ HB_PowerOut_FR : 0|8@1+ (1,0) [0|255] "" Vector__XXX

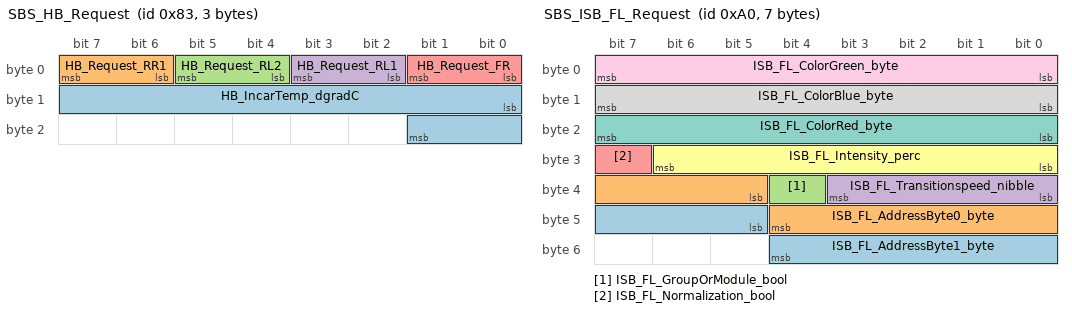
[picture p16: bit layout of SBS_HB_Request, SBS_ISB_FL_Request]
BO_ 131 SBS_HB_Request: 3 PANTHER
 SG_ HB_IncarTemp_dgradC : 8|10@1- (1,0) [-512|511] "" Vector__XXX
 SG_ HB_Request_RR1 : 6|2@1+ (1,0) [0|3] "" Vector__XXX
 SG_ HB_Request_RL2 : 4|2@1+ (1,0) [0|3] "" Vector__XXX
 SG_ HB_Request_RL1 : 2|2@1+ (1,0) [0|3] "" Vector__XXX
 SG_ HB_Request_FR : 0|2@1+ (1,0) [0|3] "" Vector__XXX

BO_ 160 SBS_ISB_FL_Request: 7 PANTHER
 SG_ ISB_FL_AddressByte1_byte : 45|8@1+ (1,0) [0|255] ""  PANTHER,PUMA_FL
 SG_ ISB_FL_AddressByte0_byte : 37|8@1+ (1,0) [0|255] ""  PANTHER,PUMA_FL
 SG_ ISB_FL_GroupOrModule_bool : 36|1@1+ (1,0) [0|1] ""  PANTHER,PUMA_FL
 SG_ ISB_FL_Transitionspeed_nibble : 32|4@1+ (1,0) [0|15] ""  PANTHER,PUMA_FL
 SG_ ISB_FL_Normalization_bool : 31|1@1+ (1,0) [0|1] ""  PANTHER,PUMA_FL
 SG_ ISB_FL_Intensity_perc : 24|7@1+ (1,0) [0|127] ""  PANTHER,PUMA_FL
 SG_ ISB_FL_ColorRed_byte : 16|8@1+ (1,0) [0|255] ""  PANTHER,PUMA_FL
 SG_ ISB_FL_ColorBlue_byte : 8|8@1+ (1,0) [0|255] ""  PANTHER,PUMA_FL
 SG_ ISB_FL_ColorGreen_byte : 0|8@1+ (1,0) [0|255] ""  PANTHER,PUMA_FL

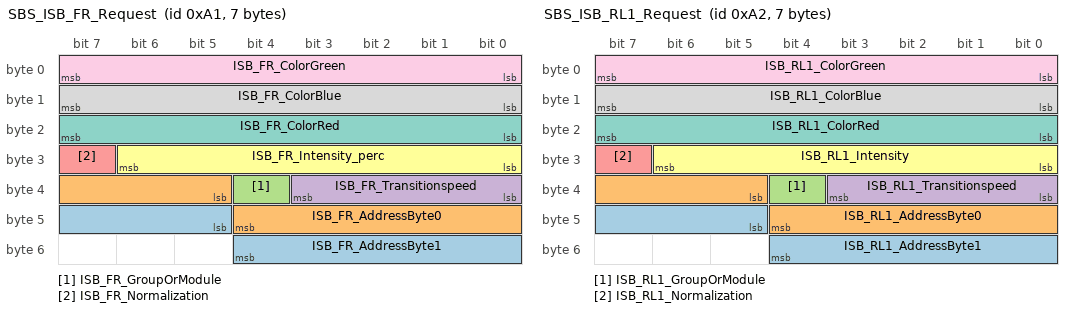
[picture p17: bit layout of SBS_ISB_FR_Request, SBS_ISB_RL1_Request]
BO_ 161 SBS_ISB_FR_Request: 7 PANTHER
 SG_ ISB_FR_AddressByte1 : 45|8@1+ (1,0) [0|255] ""  PANTHER,PUMA_FR
 SG_ ISB_FR_AddressByte0 : 37|8@1+ (1,0) [0|255] ""  PANTHER,PUMA_FR
 SG_ ISB_FR_GroupOrModule : 36|1@1+ (1,0) [0|1] ""  PANTHER,PUMA_FR
 SG_ ISB_FR_Transitionspeed : 32|4@1+ (1,0) [0|15] ""  PANTHER,PUMA_FR
 SG_ ISB_FR_Normalization : 31|1@1+ (1,0) [0|1] ""  PANTHER,PUMA_FR
 SG_ ISB_FR_Intensity_perc : 24|7@1+ (1,0) [0|127] ""  PANTHER,PUMA_FR
 SG_ ISB_FR_ColorRed : 16|8@1+ (1,0) [0|255] ""  PANTHER,PUMA_FR
 SG_ ISB_FR_ColorBlue : 8|8@1+ (1,0) [0|255] ""  PANTHER,PUMA_FR
 SG_ ISB_FR_ColorGreen : 0|8@1+ (1,0) [0|255] ""  PANTHER,PUMA_FR

BO_ 162 SBS_ISB_RL1_Request: 7 PANTHER
 SG_ ISB_RL1_AddressByte1 : 45|8@1+ (1,0) [0|255] ""  PANTHER,PUMA_R1
 SG_ ISB_RL1_AddressByte0 : 37|8@1+ (1,0) [0|255] ""  PANTHER,PUMA_R1
 SG_ ISB_RL1_GroupOrModule : 36|1@1+ (1,0) [0|1] ""  PANTHER,PUMA_R1
 SG_ ISB_RL1_Transitionspeed : 32|4@1+ (1,0) [0|15] ""  PANTHER,PUMA_R1
 SG_ ISB_RL1_Normalization : 31|1@1+ (1,0) [0|1] ""  PANTHER,PUMA_R1
 SG_ ISB_RL1_Intensity : 24|7@1+ (1,0) [0|127] ""  PANTHER,PUMA_R1
 SG_ ISB_RL1_ColorRed : 16|8@1+ (1,0) [0|255] ""  PANTHER,PUMA_R1
 SG_ ISB_RL1_ColorBlue : 8|8@1+ (1,0) [0|255] ""  PANTHER,PUMA_R1
 SG_ ISB_RL1_ColorGreen : 0|8@1+ (1,0) [0|255] ""  PANTHER,PUMA_R1

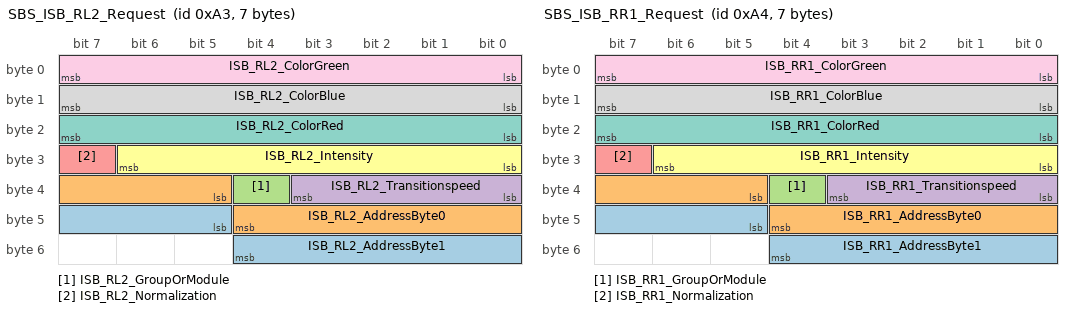
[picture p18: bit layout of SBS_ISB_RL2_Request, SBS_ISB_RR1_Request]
BO_ 163 SBS_ISB_RL2_Request: 7 PANTHER
 SG_ ISB_RL2_AddressByte1 : 45|8@1+ (1,0) [0|255] ""  PANTHER,PUMA_R2
 SG_ ISB_RL2_AddressByte0 : 37|8@1+ (1,0) [0|255] ""  PANTHER,PUMA_R2
 SG_ ISB_RL2_GroupOrModule : 36|1@1+ (1,0) [0|1] ""  PANTHER,PUMA_R2
 SG_ ISB_RL2_Transitionspeed : 32|4@1+ (1,0) [0|15] ""  PANTHER,PUMA_R2
 SG_ ISB_RL2_Normalization : 31|1@1+ (1,0) [0|1] ""  PANTHER,PUMA_R2
 SG_ ISB_RL2_Intensity : 24|7@1+ (1,0) [0|127] ""  PANTHER,PUMA_R2
 SG_ ISB_RL2_ColorRed : 16|8@1+ (1,0) [0|255] ""  PANTHER,PUMA_R2
 SG_ ISB_RL2_ColorBlue : 8|8@1+ (1,0) [0|255] ""  PANTHER,PUMA_R2
 SG_ ISB_RL2_ColorGreen : 0|8@1+ (1,0) [0|255] ""  PANTHER,PUMA_R2

BO_ 164 SBS_ISB_RR1_Request: 7 PANTHER
 SG_ ISB_RR1_AddressByte1 : 45|8@1+ (1,0) [0|255] ""  PANTHER,PUMA_RR1
 SG_ ISB_RR1_AddressByte0 : 37|8@1+ (1,0) [0|255] ""  PANTHER,PUMA_RR1
 SG_ ISB_RR1_GroupOrModule : 36|1@1+ (1,0) [0|1] ""  PANTHER,PUMA_RR1
 SG_ ISB_RR1_Transitionspeed : 32|4@1+ (1,0) [0|15] ""  PANTHER,PUMA_RR1
 SG_ ISB_RR1_Normalization : 31|1@1+ (1,0) [0|1] ""  PANTHER,PUMA_RR1
 SG_ ISB_RR1_Intensity : 24|7@1+ (1,0) [0|127] ""  PANTHER,PUMA_RR1
 SG_ ISB_RR1_ColorRed : 16|8@1+ (1,0) [0|255] ""  PANTHER,PUMA_RR1
 SG_ ISB_RR1_ColorBlue : 8|8@1+ (1,0) [0|255] ""  PANTHER,PUMA_RR1
 SG_ ISB_RR1_ColorGreen : 0|8@1+ (1,0) [0|255] ""  PANTHER,PUMA_RR1

BO_ 400 SBS_WMS_FL_Response: 4 PUMA_FL
 SG_ WMS_FL_SensorStatus : 27|3@1+ (1,0) [0|7] ""  PANTHER,CAR_PC
 SG_ WMS_FL_SpoolAngle_deg : 13|14@1+ (1,0) [0|16383] ""  PANTHER,CAR_PC
 SG_ WMS_FL_WebbingMovement : 0|13@1+ (1,0) [0|8191] ""  PANTHER,CAR_PC

BO_ 401 SBS_WMS_FR_Response: 4 PUMA_FR
 SG_ WMS_FR_SensorStatus : 27|3@1+ (1,0) [0|7] ""  PANTHER,CAR_PC
 SG_ WMS_FR_SpoolAngle : 13|14@1+ (1,0) [0|16383] ""  PANTHER,CAR_PC
 SG_ WMS_FR_WebbingMovement : 0|13@1+ (1,0) [0|8191] ""  PANTHER,CAR_PC

BO_ 402 SBS_WMS_RL1_Response: 4 PUMA_R1
 SG_ WMS_RL1_SensorStatus : 27|3@1+ (1,0) [0|7] ""  PANTHER,CAR_PC
 SG_ WMS_RL1_SpoolAngle : 13|14@1+ (1,0) [0|16383] ""  PANTHER,CAR_PC
 SG_ WMS_RL1_WebbingMovement : 0|13@1+ (1,0) [0|8191] ""  PANTHER,CAR_PC

BO_ 403 SBS_WMS_RL2_Response: 4 PUMA_R2
 SG_ WMS_RL2_SensorStatus : 27|3@1+ (1,0) [0|7] ""  PANTHER,CAR_PC
 SG_ WMS_RL2_SpoolAngle : 13|14@1+ (1,0) [0|16383] ""  PANTHER,CAR_PC
 SG_ WMS_RL2_WebbingMovement : 0|13@1+ (1,0) [0|8191] ""  PANTHER,CAR_PC

BO_ 404 SBS_WMS_RR1_Response: 4 PUMA_RR1
 SG_ WMS_RR1_SensorStatus : 27|3@1+ (1,0) [0|7] ""  PANTHER,CAR_PC
 SG_ WMS_RR1_SpoolAngle : 13|14@1+ (1,0) [0|16383] ""  PANTHER,CAR_PC
 SG_ WMS_RR1_WebbingMovement : 0|13@1+ (1,0) [0|8191] ""  PANTHER,CAR_PC

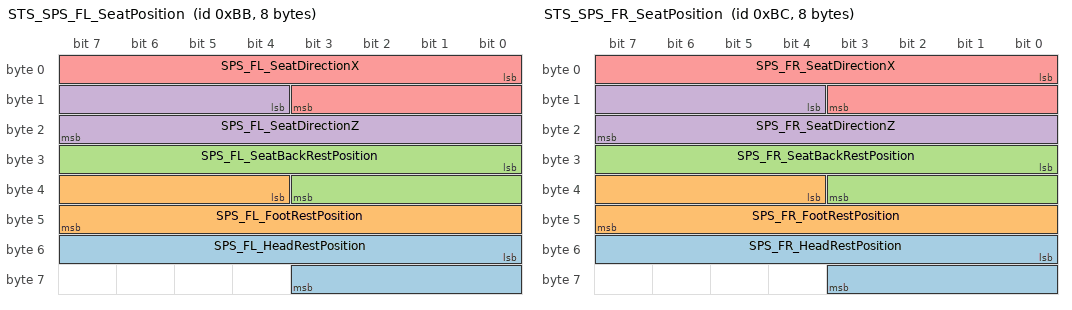
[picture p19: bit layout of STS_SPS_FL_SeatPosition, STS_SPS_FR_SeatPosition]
BO_ 187 STS_SPS_FL_SeatPosition: 8 PANTHER
 SG_ SPS_FL_HeadRestPosition : 48|12@1+ (1,0) [0|4095] ""  CAR_PC,SIMI
 SG_ SPS_FL_FootRestPosition : 36|12@1+ (1,0) [0|4095] ""  CAR_PC,SIMI
 SG_ SPS_FL_SeatBackRestPosition : 24|12@1+ (1,0) [0|4095] ""  CAR_PC,SIMI
 SG_ SPS_FL_SeatDirectionZ : 12|12@1+ (1,0) [0|4095] ""  CAR_PC,SIMI
 SG_ SPS_FL_SeatDirectionX : 0|12@1+ (1,0) [0|4095] ""  CAR_PC,SIMI

BO_ 188 STS_SPS_FR_SeatPosition: 8 PANTHER
 SG_ SPS_FR_HeadRestPosition : 48|12@1+ (1,0) [0|4095] ""  CAR_PC,SIMI
 SG_ SPS_FR_FootRestPosition : 36|12@1+ (1,0) [0|4095] ""  CAR_PC,SIMI
 SG_ SPS_FR_SeatBackRestPosition : 24|12@1+ (1,0) [0|4095] ""  CAR_PC,SIMI
 SG_ SPS_FR_SeatDirectionZ : 12|12@1+ (1,0) [0|4095] ""  CAR_PC,SIMI
 SG_ SPS_FR_SeatDirectionX : 0|12@1+ (1,0) [0|4095] ""  CAR_PC,SIMI

BO_TX_BU_ 379 : CAR_PC;
BO_TX_BU_ 380 : CAR_PC;
BO_TX_BU_ 381 : CAR_PC;
BO_TX_BU_ 382 : CAR_PC;
BO_TX_BU_ 383 : CAR_PC;
BO_TX_BU_ 371 : CAR_PC;
BO_TX_BU_ 414 : CAR_PC;
BO_TX_BU_ 413 : CAR_PC;
BO_TX_BU_ 412 : CAR_PC;
BO_TX_BU_ 184 : CAR_PC;
BO_TX_BU_ 132 : CAR_PC;
BO_TX_BU_ 513 : CAR_PC;
BO_TX_BU_ 512 : CAR_PC;
BO_TX_BU_ 196 : CAR_PC;
BO_TX_BU_ 195 : CAR_PC;
BO_TX_BU_ 194 : CAR_PC;
BO_TX_BU_ 193 : CAR_PC;
BO_TX_BU_ 181 : CAR_PC;
BO_TX_BU_ 183 : CAR_PC;
BO_TX_BU_ 191 : CAR_PC;
BO_TX_BU_ 190 : CAR_PC;
BO_TX_BU_ 189 : CAR_PC;
BO_TX_BU_ 182 : CAR_PC;
BO_TX_BU_ 415 : CAR_PC;
BO_TX_BU_ 128 : CAR_PC;
BO_TX_BU_ 129 : CAR_PC;
BO_TX_BU_ 177 : CAR_PC;
BO_TX_BU_ 130 : CAR_PC;
BO_TX_BU_ 178 : CAR_PC;
BO_TX_BU_ 179 : CAR_PC;
BO_TX_BU_ 180 : CAR_PC;
BO_TX_BU_ 176 : CAR_PC;
BO_TX_BU_ 144 : CAR_PC;
BO_TX_BU_ 384 : CAR_PC;
BO_TX_BU_ 385 : CAR_PC;
BO_TX_BU_ 386 : CAR_PC;
BO_TX_BU_ 387 : CAR_PC;
BO_TX_BU_ 388 : CAR_PC;
BO_TX_BU_ 145 : CAR_PC;
BO_TX_BU_ 392 : CAR_PC;
BO_TX_BU_ 393 : CAR_PC;
BO_TX_BU_ 394 : CAR_PC;
BO_TX_BU_ 395 : CAR_PC;
BO_TX_BU_ 396 : CAR_PC;
BO_TX_BU_ 409 : CAR_PC;
BO_TX_BU_ 146 : CAR_PC;
BO_TX_BU_ 408 : CAR_PC;
BO_TX_BU_ 411 : CAR_PC;
BO_TX_BU_ 131 : CAR_PC;
BO_TX_BU_ 160 : CAR_PC;
BO_TX_BU_ 161 : CAR_PC;
BO_TX_BU_ 162 : CAR_PC;
BO_TX_BU_ 163 : CAR_PC;
BO_TX_BU_ 164 : CAR_PC;
BO_TX_BU_ 400 : CAR_PC;
BO_TX_BU_ 401 : CAR_PC;
BO_TX_BU_ 402 : CAR_PC;
BO_TX_BU_ 403 : CAR_PC;
BO_TX_BU_ 404 : CAR_PC;
BO_TX_BU_ 187 : CAR_PC;
BO_TX_BU_ 188 : CAR_PC;

CM_ BO_ 3221225472 "This is a message for not used signals, created by Vector CANdb++ DBC OLE DB Provider.";
CM_ SG_ 379 ISB_FL_ColorGreen_Resp_byte "Color Code for ISB with RGB and Intensity requested by HMI | Signalvalues: Custom RGBA Colorcode --> A will be the intensity";
CM_ SG_ 379 ISB_FL_ColorBlue_Resp_byte "Intensity for Color Blue on FL Buckle";
CM_ SG_ 380 ISB_FR_ColorGreen_Resp "Color Code for ISB with RGB and Intensity requested by HMI | Signalvalues: Custom RGBA Colorcode --> A will be the intensity";
CM_ SG_ 381 ISB_RL1_ColorGreen_Resp "Color Code for ISB with RGB and Intensity requested by HMI | Signalvalues: Custom RGBA Colorcode --> A will be the intensity";
CM_ SG_ 382 ISB_RL2_ColorGreen_Resp "Color Code for ISB with RGB and Intensity requested by HMI | Signalvalues: Custom RGBA Colorcode --> A will be the intensity";
CM_ SG_ 383 ISB_RR1_ColorGreen_Resp "Color Code for ISB with RGB and Intensity requested by HMI | Signalvalues: Custom RGBA Colorcode --> A will be the intensity";
CM_ SG_ 181 OMS_RL1_OccupantWeightMean_kg "OMS Occupant for Weight Actuator";
CM_ SG_ 181 OMS_RL1_OccupantHeightStd_cm "OMS Occupant for Lenght Actuator";
CM_ SG_ 181 OMS_RL1_OccupantGender "OMS Torso for Angle Actuator";
CM_ SG_ 181 OMS_RL1_OutOfPosition "OMS Out Of for Position Actuator";
CM_ SG_ 181 OMS_RL1_OccupantClassification "OMS Occupant for Classification Actuator | Signalvalues: 25%, 50%, 95% Occupant";
CM_ SG_ 183 OMS_RR1_OutOfPosition "OMS Out Of for Position Actuator";
CM_ SG_ 183 OMS_RR1_OccupantWeightMean_kg "OMS Occupant for Weight Actuator";
CM_ SG_ 183 OMS_RR1_OccupantHeightStd_cm "OMS Occupant for Lenght Actuator";
CM_ SG_ 183 OMS_RR1_OccupantGender "OMS Torso for Angle Actuator";
CM_ SG_ 183 OMS_RR1_OccupantClassification "OMS Occupant for Classification Actuator | Signalvalues: 25%, 50%, 95% Occupant";
CM_ SG_ 191 SPS_RR1_HeadRestPosition "RR1 Seat HeadRest for Position Actuator | Signalvalues: mm";
CM_ SG_ 191 SPS_RR1_FootRestPosition "RR1 Seat FootRest for Position Actuator | Signalvalues: Deg";
CM_ SG_ 191 SPS_RR1_SeatBackRestPosition "RR1 Seat BackRest for Position Actuator | Signalvalues: Deg";
CM_ SG_ 191 SPS_RR1_SeatDirectionZ "RR1 Seat z-for Direction Actuator | Signalvalues: mm";
CM_ SG_ 191 SPS_RR1_SeatDirectionX "RR1 Seat x-for Direction Actuator | Signalvalues: mm";
CM_ SG_ 190 SPS_RL2_HeadRestPosition "RL2 Seat HeadRest for Position Actuator | Signalvalues: mm";
CM_ SG_ 190 SPS_RL2_FootRestPosition "RL2 Seat FootRest for Position Actuator | Signalvalues: Deg";
CM_ SG_ 190 SPS_RL2_SeatBackRestPosition "RL2 Seat BackRest for Position Actuator | Signalvalues: Deg";
CM_ SG_ 190 SPS_RL2_SeatDirectionZ "RL2 Seat z-for Direction Actuator | Signalvalues: mm";
CM_ SG_ 190 SPS_RL2_SeatDirectionX "RL2 Seat x-for Direction Actuator | Signalvalues: mm";
CM_ SG_ 189 SPS_RL1_HeadRestPosition "RL1 Seat HeadRest for Position Actuator | Signalvalues: mm";
CM_ SG_ 189 SPS_RL1_FootRestPosition "RL1 Seat FootRest for Position Actuator | Signalvalues: Deg";
CM_ SG_ 189 SPS_RL1_SeatBackRestPosition "RL1 Seat BackRest for Position Actuator | Signalvalues: Deg";
CM_ SG_ 189 SPS_RL1_SeatDirectionZ "RL1 Seat z-for Direction Actuator | Signalvalues: mm";
CM_ SG_ 189 SPS_RL1_SeatDirectionX "RL1 Seat x-for Direction Actuator | Signalvalues: mm";
CM_ SG_ 182 OMS_RL2_OutOfPosition "OMS Out Of for Position Actuator";
CM_ SG_ 182 OMS_RL2_OccupantWeightMean_kg "OMS Occupant for Weight Actuator";
CM_ SG_ 182 OMS_RL2_OccupantHeightStd_cm "OMS Occupant for Lenght Actuator";
CM_ SG_ 182 OMS_RL2_OccupantGender "OMS Torso for Angle Actuator";
CM_ SG_ 182 OMS_RL2_OccupantClassification "OMS Occupant for Classification Actuator | Signalvalues: 25%, 50%, 95% Occupant";
CM_ SG_ 128 HMI_CrashImpactTrigger "Trigger bit that the crash happens right now";
CM_ SG_ 128 HMI_CrashSeverity "Crash Severity Selection from HMI | Signalvalues: 0 = nothing
1 = 32kmh (low severity)
2 = 56km/h (high severity)";
CM_ SG_ 129 HMI_SEAL_ActivationRequest "HMI SILG Activation for Request Actuator | Signalvalues: 0 = Nothing
1 = Blow in
2 = Blow out";
CM_ SG_ 177 ARS_FR_InjuryRiskNonAdaptive "Calulated Injurity Risk by Adaptive Restraint Algo based on non adaptive restraint system parameter";
CM_ SG_ 177 ARS_FR_InjuryRiskAdaptive "Calulated Injurity Risk based on the Adaptive Restrain Parameter";
CM_ SG_ 177 ARS_FL_InjuryRiskNonAdaptive "Calulated Injurity Risk by Adaptive Restraint Algo based on non adaptive restraint system parameter";
CM_ SG_ 177 ARS_FL_InjuryRiskAdaptive "Calulated Injurity Risk based on the Adaptive Restrain Parameter";
CM_ SG_ 130 ARS_MSLL_ActivationRequest "Trigger signal from active restraint system";
CM_ SG_ 178 ARS_FR_TimeToFireSeatbelt "ARS TimeToFire for Seatbelt Actuator";
CM_ SG_ 178 ARS_FR_TimeToFireAirbag "ARS TimeToFire for Airbag Vent";
CM_ SG_ 178 ARS_FL_TimeToFireSeatbelt "ARS TimeToFire for Seatbelt Actuator";
CM_ SG_ 178 ARS_FL_TimeToFireAirbag "ARS TimeToFire for Airbag Vent";
CM_ SG_ 179 OMS_FL_OccupantGender "DMS Torso for Angle Actuator";
CM_ SG_ 179 OMS_FL_OccupantHeightMean_cm "DMS Occupant for Lenght Actuator";
CM_ SG_ 179 OMS_FL_OccupantWeightMean_kg "DMS Occupant for Weight Actuator";
CM_ SG_ 179 OMS_FL_OutOfPosition "DMS Out Of for Position Actuator";
CM_ SG_ 179 OMS_FL_OccupantClassification "DMS Occupant for Classification Actuator | Signalvalues: 25%, 50%, 95% Occupant";
CM_ SG_ 179 OMS_FL_HandsOnWheel "DMS Hands on for Wheel Actuator | Signalvalues: 0 = Hands off Wheel
1 = Hands on Wheel";
CM_ SG_ 180 OMS_FR_OccupantGender "OMS Torso for Angle Actuator";
CM_ SG_ 180 OMS_FR_OccupantHeightStd_cm "OMS Occupant for Lenght Actuator";
CM_ SG_ 180 OMS_FR_OccupantWeightMean_kg "OMS Occupant for Weight Actuator";
CM_ SG_ 180 OMS_FR_OutOfPosition "OMS Out Of for Position Actuator";
CM_ SG_ 180 OMS_FR_OccupantClassification "OMS Occupant for Classification Actuator | Signalvalues: 25%, 50%, 95% Occupant";
CM_ SG_ 176 SMA_VehicleStable "Calulated Vehicle Stable by SMA | Signalvalues: 0 = vehicle unstable
1 = vehicle stable";
CM_ SG_ 144 ABL_RR1_RetractRequest "Manual ABL Retraction request by HMI | Signalvalues: 0 = nothing
1 = Offer Position
2 = S0 Position
3 = Dynamic
4 = Pre Crash
5 = Haptic
11 = Wake Up
12 = Park Position";
CM_ SG_ 144 ABL_RL2_RetractRequest "Manual ABL Retraction request by HMI | Signalvalues: 0 = nothing
1 = Offer Position
2 = S0 Position
3 = Dynamic
4 = Pre Crash
5 = Haptic
11 = Wake Up
12 = Park Position";
CM_ SG_ 144 ABL_RL1_RetractRequest "Manual ABL Retraction request by HMI | Signalvalues: 0 = nothing
1 = Offer Position
2 = S0 Position
3 = Dynamic
4 = Pre Crash
5 = Haptic
11 = Wake Up
12 = Park Position";
CM_ SG_ 144 ABL_FR_RetractRequest "Manual ABL Retraction request by HMI | Signalvalues: 0 = nothing
1 = Offer Position
2 = S0 Position
3 = Dynamic
4 = Pre Crash
5 = Haptic
11 = Wake Up
12 = Park Position";
CM_ SG_ 144 ABL_FL_RetractRequest "Manual ABL Retraction request by HMI | Signalvalues: 0 = nothing
1 = Offer Position
2 = S0 Position
3 = Dynamic
4 = Pre Crash
5 = Haptic
11 = Wake Up
12 = Park Position";
CM_ SG_ 384 ABL_FL_ActivationPhase "FL ABL Actuator Execution Phase for Status Actuator | Signalvalues: 0 = No activation
1 = Welcome
12 = S0 Calibration
21 = Buckle Lift
31 = Beltpark
41 = Beltslack Removal
51 = Haptic Warning
71 = Retract 1
72 = Retract 2
81 = Release
74 = Reverse
90 = PTMP direct demand";
CM_ SG_ 384 ABL_FL_ActivationLevelStatus "FL ABL Actuator Activation Level for Status Actuator | Signalvalues: 0 = No activation
1 = Welcome Request
11 = Diagnoses Pulse
12 = S0 calibration
21 = Buckle Lift
22 = Buckle Lift Post Crash
31 - Beltpark Support
41 = Beltslack Removal
51 = Haptic Warning
61 = Dynamic Support
71 = Retract Level 1
72 = Retract Level 2
73 = Retract Level 3
74 = Retract Level 4
75 = Retract Level 5
76 = Retract Level 6
77 = Retract Level 7
78 = Retract Level 8
79 = Retract Level 9
81 = Safety Release
95 = PTMP Position Demand
96 = PTMP Speed Demand
97 = PTMP Current Demand
98 = PTMP Voltage Demand
99 = PTMP Dutycycle Demand";
CM_ SG_ 384 ABL_FL_S0SensorStatus_bool "FL ABL S0 Sensor for Status Actuator | Signalvalues: 0 = Not in S0 position
1 = S0 position reached";
CM_ SG_ 385 ABL_FR_ActivationPhase "FR ABL Actuator Execution Phase for Status Actuator | Signalvalues: 0 = No activation
1 = Welcome
12 = S0 Calibration
21 = Buckle Lift
31 = Beltpark
41 = Beltslack Removal
51 = Haptic Warning
71 = Retract 1
72 = Retract 2
81 = Release
74 = Reverse
90 = PTMP direct demand";
CM_ SG_ 385 ABL_FR_ActivationLevelStatus "FR ABL Actuator Activation Level for Status Actuator | Signalvalues: 0 = No activation
1 = Welcome Request
11 = Diagnoses Pulse
12 = S0 calibration
21 = Buckle Lift
22 = Buckle Lift Post Crash
31 - Beltpark Support
41 = Beltslack Removal
51 = Haptic Warning
61 = Dynamic Support
71 = Retract Level 1
72 = Retract Level 2
73 = Retract Level 3
74 = Retract Level 4
75 = Retract Level 5
76 = Retract Level 6
77 = Retract Level 7
78 = Retract Level 8
79 = Retract Level 9
81 = Safety Release
95 = PTMP Position Demand
96 = PTMP Speed Demand
97 = PTMP Current Demand
98 = PTMP Voltage Demand
99 = PTMP Dutycycle Demand";
CM_ SG_ 385 ABL_FR_S0SensorStatus_bool "FR ABL S0 Sensor for Status Actuator | Signalvalues: 0 = Not in S0 position
1 = S0 position reached";
CM_ SG_ 386 ABL_RL1_ActivationPhase "RL1 ABL Actuator Execution Phase for Status Actuator | Signalvalues: 0 = No activation
1 = Welcome
12 = S0 Calibration
21 = Buckle Lift
31 = Beltpark
41 = Beltslack Removal
51 = Haptic Warning
71 = Retract 1
72 = Retract 2
81 = Release
74 = Reverse
90 = PTMP direct demand";
CM_ SG_ 386 ABL_RL1_S0SensorStatus_bool "RL1 ABL S0 Sensor for Status Actuator | Signalvalues: 0 = Not in S0 position
1 = S0 position reached";
CM_ SG_ 387 ABL_RL2_ActivationPhase "R2 ABL Actuator Execution Phase for Status Actuator | Signalvalues: 0 = No activation
1 = Welcome
12 = S0 Calibration
21 = Buckle Lift
31 = Beltpark
41 = Beltslack Removal
51 = Haptic Warning
71 = Retract 1
72 = Retract 2
81 = Release
74 = Reverse
90 = PTMP direct demand";
CM_ SG_ 387 ABL_RL2_S0SensorStatus_bool "R2 ABL S0 Sensor for Status Actuator | Signalvalues: 0 = Not in S0 position
1 = S0 position reached";
CM_ SG_ 388 ABL_RR1_ActivationPhase "RR1 ABL Actuator Execution Phase for Status Actuator | Signalvalues: 0 = No activation
1 = Welcome
12 = S0 Calibration
21 = Buckle Lift
31 = Beltpark
41 = Beltslack Removal
51 = Haptic Warning
71 = Retract 1
72 = Retract 2
81 = Release
74 = Reverse
90 = PTMP direct demand";
CM_ SG_ 388 ABL_RR1_ActivationLevelStatus "RR1 ABL Actuator Activation Level for Status Actuator | Signalvalues: 0 = No activation
1 = Welcome Request
11 = Diagnoses Pulse
12 = S0 calibration
21 = Buckle Lift
22 = Buckle Lift Post Crash
31 - Beltpark Support
41 = Beltslack Removal
51 = Haptic Warning
61 = Dynamic Support
71 = Retract Level 1
72 = Retract Level 2
73 = Retract Level 3
74 = Retract Level 4
75 = Retract Level 5
76 = Retract Level 6
77 = Retract Level 7
78 = Retract Level 8
79 = Retract Level 9
81 = Safety Release
95 = PTMP Position Demand
96 = PTMP Speed Demand
97 = PTMP Current Demand
98 = PTMP Voltage Demand
99 = PTMP Dutycycle Demand";
CM_ SG_ 388 ABL_RR1_S0SensorStatus_bool "RR1 ABL S0 Sensor for Status Actuator | Signalvalues: 0 = Not in S0 position
1 = S0 position reached";
CM_ SG_ 145 ACR_RR1_RetractRequest "Manual ACR Retraction request by HMI";
CM_ SG_ 145 ACR_RL2_RetractRequest "Manual ACR Retraction request by HMI";
CM_ SG_ 145 ACR_RL1_RetractRequest "Manual ACR Retraction request by HMI";
CM_ SG_ 145 ACR_FR_RetractRequest "Manual ACR Retraction request by HMI";
CM_ SG_ 145 ACR_FL_RetractRequest "Manual ACR Retraction request by HMI";
CM_ SG_ 392 ACR_FL_SpoolFasterClutch "FL ACR Motor for Speed Actuator";
CM_ SG_ 392 ACR_FL_ActivationPhase "FL ACR Actuator Execution Phase for Status Actuator";
CM_ SG_ 392 ACR_FL_ActivationLevelStatus "FL ACR Actuator Activation Level for Status Actuator | Signalvalues: 0 - No activation.
11 - Diagnoses Pulse.
16 - PTMP demanded Motor Speed and Current Limit.
17 - PTMP demanded Motor Current.
18 - PTMP demanded Motor Voltage.
19 - PTMP demanded Motor PWM Dutycycle and direction.
29 - BeltPark Level 1
30 - BeltPark Level 2
31 - Beltslack Reduction.
32 - Haptic Warning Level 1
33 - Haptic Warning Level 2
34 - Haptic Warning Level 3
35 - Haptic Warning Level 4
36 - Haptic Warning Level 5
37 - Haptic Warning Level 6
41 - Retract Level 1.
42 - Retract Level 2.
43 - Retract Level 3.
44 - Retract Level 4.
45 - Retract Level 5.
46 - Retract Level 6.
47 - Retract Level 7.
48 - Dynamik Belt.
49 - Retract Level 9.
51 - RePos level 1 request.
52 - RePos level 2 request.
53 - RePos level 3 request.";
CM_ SG_ 393 ACR_FR_SpoolFasterClutch "FR ACR Motor for Speed Actuator";
CM_ SG_ 393 ACR_FR_ActivationPhase "FR ACR Actuator Execution Phase for Status Actuator";
CM_ SG_ 393 ACR_FR_ActivationLevelStatus "FR ACR Actuator Activation Level for Status Actuator | Signalvalues: 0 - No activation.
11 - Diagnoses Pulse.
16 - PTMP demanded Motor Speed and Current Limit.
17 - PTMP demanded Motor Current.
18 - PTMP demanded Motor Voltage.
19 - PTMP demanded Motor PWM Dutycycle and direction.
29 - BeltPark Level 1
30 - BeltPark Level 2
31 - Beltslack Reduction.
32 - Haptic Warning Level 1
33 - Haptic Warning Level 2
34 - Haptic Warning Level 3
35 - Haptic Warning Level 4
36 - Haptic Warning Level 5
37 - Haptic Warning Level 6
41 - Retract Level 1.
42 - Retract Level 2.
43 - Retract Level 3.
44 - Retract Level 4.
45 - Retract Level 5.
46 - Retract Level 6.
47 - Retract Level 7.
48 - Dynamik Belt.
49 - Retract Level 9.
51 - RePos level 1 request.
52 - RePos level 2 request.
53 - RePos level 3 request.";
CM_ SG_ 394 ACR_RL1_SpoolFasterClutch "RL1 ACR Motor for Speed Actuator";
CM_ SG_ 394 ACR_RL1_ActivationPhase "RL1 ACR Actuator Execution Phase for Status Actuator";
CM_ SG_ 395 ACR_RL2_SpoolFasterClutch "R2 ACR Motor for Speed Actuator";
CM_ SG_ 395 ACR_RL2_ActivationPhase "R2 ACR Actuator Execution Phase for Status Actuator";
CM_ SG_ 396 ACR_RR1_SpoolFasterClutch "RR1 ACR Motor for Speed Actuator";
CM_ SG_ 396 ACR_RR1_ActivationPhase "RR1 ACR Actuator Execution Phase for Status Actuator";
CM_ SG_ 396 ACR_RR1_ActivationLevelStatus "RR1 ACR Actuator Activation Level for Status Actuator | Signalvalues: 0 - No activation.
11 - Diagnoses Pulse.
16 - PTMP demanded Motor Speed and Current Limit.
17 - PTMP demanded Motor Current.
18 - PTMP demanded Motor Voltage.
19 - PTMP demanded Motor PWM Dutycycle and direction.
29 - BeltPark Level 1
30 - BeltPark Level 2
31 - Beltslack Reduction.
32 - Haptic Warning Level 1
33 - Haptic Warning Level 2
34 - Haptic Warning Level 3
35 - Haptic Warning Level 4
36 - Haptic Warning Level 5
37 - Haptic Warning Level 6
41 - Retract Level 1.
42 - Retract Level 2.
43 - Retract Level 3.
44 - Retract Level 4.
45 - Retract Level 5.
46 - Retract Level 6.
47 - Retract Level 7.
48 - Dynamik Belt.
49 - Retract Level 9.
51 - RePos level 1 request.
52 - RePos level 2 request.
53 - RePos level 3 request.";
CM_ SG_ 409 BSW_RR1_BuckleStatus "Buckle Switch Status | Signalvalues: Buckled, Unbuckled";
CM_ SG_ 409 BSW_RL2_BuckleStatus "Buckle Switch Status | Signalvalues: Buckled, Unbuckled";
CM_ SG_ 409 BSW_RL1_BuckleStatus "Buckle Switch Status | Signalvalues: Buckled, Unbuckled";
CM_ SG_ 409 BSW_FR_BuckleStatus "Buckle Switch Status | Signalvalues: Buckled, Unbuckled";
CM_ SG_ 409 BSW_FL_BuckleStatus "Buckle Switch Status | Signalvalues: Buckled, Unbuckled";
CM_ SG_ 146 ELK_FL_LockingRequest "Manual Locking Request from HMI | Signalvalues: Lock, No Lock";
CM_ SG_ 146 ELK_FR_LockingRequest "Manual Locking Request from HMI | Signalvalues: Lock, No Lock";
CM_ SG_ 146 ELK_RR1_LockingRequest "Manual Locking Request from HMI | Signalvalues: Lock, No Lock";
CM_ SG_ 146 ELK_RL2_LockingRequest "Manual Locking Request from HMI | Signalvalues: Lock, No Lock";
CM_ SG_ 146 ELK_RL1_LockingRequest "Manual Locking Request from HMI | Signalvalues: Lock, No Lock";
CM_ SG_ 408 ELK_RR1_LockingStatus "E-Locking Status for RR1 Actuator | Signalvalues: Lock, No Lock";
CM_ SG_ 408 ELK_RL2_LockingStatus "E-Locking Status for R2 Actuator | Signalvalues: Lock, No Lock";
CM_ SG_ 408 ELK_RL1_LockingStatus "E-Locking Status for R1 Actuator | Signalvalues: Lock, No Lock";
CM_ SG_ 408 ELK_FR_LockingStatus "E-Locking Status for FR Actuator | Signalvalues: Lock, No Lock";
CM_ SG_ 408 ELK_FL_LockingStatus "E-Locking Status for FL Actuator | Signalvalues: Lock, No Lock";
CM_ SG_ 160 ISB_FL_ColorBlue_byte "Intensity for Color Blue on FL Buckle";
CM_ SG_ 160 ISB_FL_ColorGreen_byte "Color Code for ISB with RGB and Intensity requested by HMI | Signalvalues: Custom RGBA Colorcode --> A will be the intensity";
CM_ SG_ 161 ISB_FR_ColorGreen "Color Code for ISB with RGB and Intensity requested by HMI | Signalvalues: Custom RGBA Colorcode --> A will be the intensity";
CM_ SG_ 162 ISB_RL1_ColorGreen "Color Code for ISB with RGB and Intensity requested by HMI | Signalvalues: Custom RGBA Colorcode --> A will be the intensity";
CM_ SG_ 163 ISB_RL2_ColorGreen "Color Code for ISB with RGB and Intensity requested by HMI | Signalvalues: Custom RGBA Colorcode --> A will be the intensity";
CM_ SG_ 164 ISB_RR1_ColorGreen "Color Code for ISB with RGB and Intensity requested by HMI | Signalvalues: Custom RGBA Colorcode --> A will be the intensity";
CM_ SG_ 400 WMS_FL_WebbingMovement "Webbing Payout measured by ACR spool rotation | Signalvalues: 0-max mm";
CM_ SG_ 401 WMS_FR_WebbingMovement "Webbing Payout measured by ACR spool rotation | Signalvalues: 0-max mm";
CM_ SG_ 402 WMS_RL1_WebbingMovement "Webbing Payout measured by ACR spool rotation | Signalvalues: 0-max mm";
CM_ SG_ 403 WMS_RL2_WebbingMovement "Webbing Payout measured by ACR spool rotation | Signalvalues: 0-max mm";
CM_ SG_ 404 WMS_RR1_WebbingMovement "Webbing Payout measured by ACR spool rotation | Signalvalues: 0-max mm";
CM_ SG_ 187 SPS_FL_HeadRestPosition "FL Seat HeadRest for Position Actuator | Signalvalues: mm";
CM_ SG_ 187 SPS_FL_FootRestPosition "FL Seat FootRest for Position Actuator | Signalvalues: Deg";
CM_ SG_ 187 SPS_FL_SeatBackRestPosition "FL Seat BackRest for Position Actuator | Signalvalues: Deg";
CM_ SG_ 187 SPS_FL_SeatDirectionZ "FL Seat z-for Direction Actuator | Signalvalues: mm";
CM_ SG_ 187 SPS_FL_SeatDirectionX "FL Seat x-for Direction Actuator | Signalvalues: mm";
CM_ SG_ 188 SPS_FR_HeadRestPosition "FR Seat HeadRest for Position Actuator | Signalvalues: mm";
CM_ SG_ 188 SPS_FR_FootRestPosition "FR Seat FootRest for Position Actuator | Signalvalues: Deg";
CM_ SG_ 188 SPS_FR_SeatBackRestPosition "FR Seat BackRest for Position Actuator | Signalvalues: Deg";
CM_ SG_ 188 SPS_FR_SeatDirectionZ "FR Seat z-for Direction Actuator | Signalvalues: mm";
CM_ SG_ 188 SPS_FR_SeatDirectionX "FR Seat x-for Direction Actuator | Signalvalues: mm";
BA_DEF_ SG_  "GenSigFuncType" ENUM  "NoFunction";
BA_DEF_ SG_  "GenSigSendType" ENUM  "Cyclic","Spontan";
BA_DEF_ SG_  "GenSigAutoGenDsp" ENUM  "YES";
BA_DEF_ SG_  "GenSigAutoGenSnd" ENUM  "<n.a.>";
BA_DEF_ SG_  "GenSigStartValue" FLOAT -100000000000 100000000000;
BA_DEF_ BO_  "Gen_Msg_Cycletime" INT 0 65535;
BA_DEF_ BO_  "GenMsgILSupport" ENUM  "YES";
BA_DEF_ BO_  "GenMsgSendType" ENUM  "cyclicX","spontanX";
BA_DEF_ BO_  "GenMsgAutoGenDsp" ENUM  "YES";
BA_DEF_ BO_  "GenMsgAutoGenSnd" ENUM  "YES";
BA_DEF_ BO_  "GenMsgCycleTime" INT 0 1000000;
BA_DEF_ BO_  "GenMsgSendType2" ENUM  "Zyklisch","Ereignisgesteuert","Auf Anfrage","dummy";
BA_DEF_ BO_  "GenMsgSendType3" ENUM  "Zyklisch","Ereignisgesteuert","Auf Anfrage","dummy";
BA_DEF_ BO_  "GenMsgSendType4" ENUM  "Zyklisch","Ereignisgesteuert","Auf Anfrage","dummy";
BA_DEF_ BO_  "GenMsgSendType5" ENUM  "Zyklisch","Ereignisgesteuert","Auf Anfrage","dummy";
BA_DEF_ BO_  "GenMsgSendType6" ENUM  "Zyklisch","Ereignisgesteuert","Auf Anfrage","dummy";
BA_DEF_ BO_  "GenMsgSendType7" ENUM  "Zyklisch","Ereignisgesteuert","Auf Anfrage","dummy";
BA_DEF_ BO_  "GenMsgSendType8" ENUM  "Zyklisch","Ereignisgesteuert","Auf Anfrage","dummy";
BA_DEF_ BO_  "GenMsgSendType9" ENUM  "Zyklisch","Ereignisgesteuert","Auf Anfrage","dummy";
BA_DEF_ BO_  "GenMsgSendType10" ENUM  "Zyklisch","Ereignisgesteuert","Auf Anfrage","dummy";
BA_DEF_ BO_  "GenMsgSendType11" ENUM  "Zyklisch","Ereignisgesteuert","Auf Anfrage","dummy";
BA_DEF_ BO_  "GenMsgSendType12" ENUM  "Zyklisch","Ereignisgesteuert","Auf Anfrage","dummy";
BA_DEF_ BO_  "GenMsgSendType13" ENUM  "Zyklisch","Ereignisgesteuert","Auf Anfrage","dummy";
BA_DEF_ BO_  "GenMsgSendType14" ENUM  "Zyklisch","Ereignisgesteuert","Auf Anfrage","dummy";
BA_DEF_ BO_  "GenMsgSendType15" ENUM  "Zyklisch","Ereignisgesteuert","Auf Anfrage","dummy";
BA_DEF_ BO_  "GenMsgSendType16" ENUM  "Zyklisch","Ereignisgesteuert","Auf Anfrage","dummy";
BA_DEF_ BO_  "GenMsgSendType17" ENUM  "Zyklisch","Ereignisgesteuert","Auf Anfrage","dummy";
BA_DEF_ BO_  "GenMsgSendType18" ENUM  "Zyklisch","Ereignisgesteuert","Auf Anfrage","dummy";
BA_DEF_ BO_  "GenMsgSendType19" ENUM  "Zyklisch","Ereignisgesteuert","Auf Anfrage","dummy";
BA_DEF_ BO_  "GenMsgSendType20" ENUM  "Zyklisch","Ereignisgesteuert","Auf Anfrage","dummy";
BA_DEF_ BO_  "GenMsgSendType21" ENUM  "Zyklisch","Ereignisgesteuert","Auf Anfrage","dummy";
BA_DEF_ BO_  "GenMsgSendType22" ENUM  "Zyklisch","Ereignisgesteuert","Auf Anfrage","dummy";
BA_DEF_ BO_  "GenMsgSendType23" ENUM  "Zyklisch","Ereignisgesteuert","Auf Anfrage","dummy";
BA_DEF_ BO_  "GenMsgSendType24" ENUM  "Zyklisch","Ereignisgesteuert","Auf Anfrage","dummy";
BA_DEF_ BO_  "GenMsgSendType25" ENUM  "Zyklisch","Ereignisgesteuert","Auf Anfrage","dummy";
BA_DEF_ BO_  "GenMsgSendType26" ENUM  "Zyklisch","Ereignisgesteuert","Auf Anfrage","dummy";
BA_DEF_ BO_  "GenMsgSendType27" ENUM  "Zyklisch","Ereignisgesteuert","Auf Anfrage","dummy";
BA_DEF_ BO_  "GenMsgSendType28" ENUM  "Zyklisch","Ereignisgesteuert","Auf Anfrage","dummy";
BA_DEF_ BO_  "GenMsgSendType29" ENUM  "Zyklisch","Ereignisgesteuert","Auf Anfrage","dummy";
BA_DEF_ BO_  "GenMsgSendType30" ENUM  "Zyklisch","Ereignisgesteuert","Auf Anfrage","dummy";
BA_DEF_ BO_  "GenMsgSendType31" ENUM  "Zyklisch","Ereignisgesteuert","Auf Anfrage","dummy";
BA_DEF_ BO_  "GenMsgSendType32" ENUM  "Zyklisch","Ereignisgesteuert","Auf Anfrage","dummy";
BA_DEF_ BO_  "GenMsgSendType33" ENUM  "Zyklisch","Ereignisgesteuert","Auf Anfrage","dummy";
BA_DEF_ BO_  "GenMsgSendType34" ENUM  "Zyklisch","Ereignisgesteuert","Auf Anfrage","dummy";
BA_DEF_ BO_  "GenMsgSendType35" ENUM  "Zyklisch","Ereignisgesteuert","Auf Anfrage","dummy";
BA_DEF_ BU_  "ILUsed" ENUM  "YES";
BA_DEF_ BU_  "GenNodAutoGenDsp" ENUM  "YES";
BA_DEF_ BU_  "GenNodAutoGenSnd" ENUM  "YES";
BA_DEF_ BU_  "MessageManagerUsed" ENUM  "no","yes";
BA_DEF_ BU_  "NodeLayerModules" STRING ;
BA_DEF_ BU_  "NmAsrCanMsgReducedTime" INT 0 65535;
BA_DEF_  "Manufacturer" ENUM  "DBAG","VAG","BMWAG";
BA_DEF_  "NmAsrTimeoutTime" INT 0 65535;
BA_DEF_  "NmAsrWaitBusSleepTime" INT 0 65535;
BA_DEF_  "NmAsrRepeatMessageTime" INT 0 65535;
BA_DEF_  "NmAsrCanMsgCycleTime" INT 0 65535;
BA_DEF_  "NmAsrCanMsgTxTimeoutTime" INT 0 65535;
BA_DEF_  "NmAsrBaseAddress" HEX 0 2047;
BA_DEF_  "NmAsrMessageCount" INT 1 255;
BA_DEF_  "NmType" STRING ;
BA_DEF_  "Manufacturer_ALT" ENUM  "DBAG","VAG","BMWAG","PAG","GM";
BA_DEF_DEF_  "GenSigFuncType" "NoFunction";
BA_DEF_DEF_  "GenSigSendType" "Cyclic";
BA_DEF_DEF_  "GenSigAutoGenDsp" "YES";
BA_DEF_DEF_  "GenSigAutoGenSnd" "<n.a.>";
BA_DEF_DEF_  "GenSigStartValue" 0;
BA_DEF_DEF_  "Gen_Msg_Cycletime" 0;
BA_DEF_DEF_  "GenMsgILSupport" "YES";
BA_DEF_DEF_  "GenMsgSendType" "cyclicX";
BA_DEF_DEF_  "GenMsgAutoGenDsp" "YES";
BA_DEF_DEF_  "GenMsgAutoGenSnd" "YES";
BA_DEF_DEF_  "GenMsgCycleTime" 0;
BA_DEF_DEF_  "GenMsgSendType2" "Zyklisch";
BA_DEF_DEF_  "GenMsgSendType3" "Zyklisch";
BA_DEF_DEF_  "GenMsgSendType4" "Zyklisch";
BA_DEF_DEF_  "GenMsgSendType5" "Zyklisch";
BA_DEF_DEF_  "GenMsgSendType6" "Zyklisch";
BA_DEF_DEF_  "GenMsgSendType7" "Zyklisch";
BA_DEF_DEF_  "GenMsgSendType8" "Zyklisch";
BA_DEF_DEF_  "GenMsgSendType9" "Zyklisch";
BA_DEF_DEF_  "GenMsgSendType10" "Zyklisch";
BA_DEF_DEF_  "GenMsgSendType11" "Zyklisch";
BA_DEF_DEF_  "GenMsgSendType12" "Zyklisch";
BA_DEF_DEF_  "GenMsgSendType13" "Zyklisch";
BA_DEF_DEF_  "GenMsgSendType14" "Zyklisch";
BA_DEF_DEF_  "GenMsgSendType15" "Zyklisch";
BA_DEF_DEF_  "GenMsgSendType16" "Zyklisch";
BA_DEF_DEF_  "GenMsgSendType17" "Zyklisch";
BA_DEF_DEF_  "GenMsgSendType18" "Zyklisch";
BA_DEF_DEF_  "GenMsgSendType19" "Zyklisch";
BA_DEF_DEF_  "GenMsgSendType20" "Zyklisch";
BA_DEF_DEF_  "GenMsgSendType21" "Zyklisch";
BA_DEF_DEF_  "GenMsgSendType22" "Zyklisch";
BA_DEF_DEF_  "GenMsgSendType23" "Zyklisch";
BA_DEF_DEF_  "GenMsgSendType24" "Zyklisch";
BA_DEF_DEF_  "GenMsgSendType25" "Zyklisch";
BA_DEF_DEF_  "GenMsgSendType26" "Zyklisch";
BA_DEF_DEF_  "GenMsgSendType27" "Zyklisch";
BA_DEF_DEF_  "GenMsgSendType28" "Zyklisch";
BA_DEF_DEF_  "GenMsgSendType29" "Zyklisch";
BA_DEF_DEF_  "GenMsgSendType30" "Zyklisch";
BA_DEF_DEF_  "GenMsgSendType31" "Zyklisch";
BA_DEF_DEF_  "GenMsgSendType32" "Zyklisch";
BA_DEF_DEF_  "GenMsgSendType33" "Zyklisch";
BA_DEF_DEF_  "GenMsgSendType34" "Zyklisch";
BA_DEF_DEF_  "GenMsgSendType35" "Zyklisch";
BA_DEF_DEF_  "ILUsed" "YES";
BA_DEF_DEF_  "GenNodAutoGenDsp" "YES";
BA_DEF_DEF_  "GenNodAutoGenSnd" "YES";
BA_DEF_DEF_  "MessageManagerUsed" "yes";
BA_DEF_DEF_  "NodeLayerModules" "AsrNM_BMW.dll";
BA_DEF_DEF_  "NmAsrCanMsgReducedTime" 640;
BA_DEF_DEF_  "Manufacturer" "BMWAG";
BA_DEF_DEF_  "NmAsrTimeoutTime" 2000;
BA_DEF_DEF_  "NmAsrWaitBusSleepTime" 1500;
BA_DEF_DEF_  "NmAsrRepeatMessageTime" 3200;
BA_DEF_DEF_  "NmAsrCanMsgCycleTime" 640;
BA_DEF_DEF_  "NmAsrCanMsgTxTimeoutTime" 1920;
BA_DEF_DEF_  "NmAsrBaseAddress" 1280;
BA_DEF_DEF_  "NmAsrMessageCount" 128;
BA_DEF_DEF_  "NmType" "NmAsr";
BA_DEF_DEF_  "Manufacturer_ALT" "BMWAG";
BA_ "Gen_Msg_Cycletime" BO_ 379 10;
BA_ "Gen_Msg_Cycletime" BO_ 380 10;
BA_ "Gen_Msg_Cycletime" BO_ 381 10;
BA_ "Gen_Msg_Cycletime" BO_ 382 10;
BA_ "Gen_Msg_Cycletime" BO_ 383 10;
BA_ "GenMsgCycleTime" BO_ 371 10;
BA_ "GenMsgCycleTime" BO_ 414 100;
BA_ "GenMsgCycleTime" BO_ 413 100;
BA_ "GenMsgCycleTime" BO_ 412 100;
BA_ "GenMsgCycleTime" BO_ 184 100;
BA_ "GenMsgCycleTime" BO_ 512 10;
BA_ "GenMsgCycleTime" BO_ 196 10;
BA_ "GenMsgCycleTime" BO_ 195 10;
BA_ "GenMsgCycleTime" BO_ 194 10;
BA_ "GenMsgCycleTime" BO_ 193 10;
BA_ "GenMsgCycleTime" BO_ 181 10;
BA_ "GenMsgCycleTime" BO_ 183 10;
BA_ "GenMsgCycleTime" BO_ 191 10;
BA_ "GenMsgCycleTime" BO_ 190 10;
BA_ "GenMsgCycleTime" BO_ 189 10;
BA_ "GenMsgCycleTime" BO_ 182 10;
BA_ "GenMsgCycleTime" BO_ 415 10;
BA_ "GenMsgCycleTime" BO_ 128 1;
BA_ "GenMsgCycleTime" BO_ 129 1;
BA_ "GenMsgCycleTime" BO_ 177 10;
BA_ "GenMsgCycleTime" BO_ 130 10;
BA_ "GenMsgCycleTime" BO_ 178 10;
BA_ "GenMsgCycleTime" BO_ 179 10;
BA_ "GenMsgCycleTime" BO_ 180 10;
BA_ "GenMsgCycleTime" BO_ 176 10;
BA_ "GenMsgCycleTime" BO_ 144 10;
BA_ "GenMsgCycleTime" BO_ 384 10;
BA_ "GenMsgCycleTime" BO_ 385 10;
BA_ "GenMsgCycleTime" BO_ 386 10;
BA_ "GenMsgCycleTime" BO_ 387 10;
BA_ "GenMsgCycleTime" BO_ 388 10;
BA_ "GenMsgCycleTime" BO_ 145 10;
BA_ "GenMsgCycleTime" BO_ 392 10;
BA_ "GenMsgCycleTime" BO_ 393 10;
BA_ "GenMsgCycleTime" BO_ 394 10;
BA_ "GenMsgCycleTime" BO_ 395 10;
BA_ "GenMsgCycleTime" BO_ 396 10;
BA_ "GenMsgCycleTime" BO_ 409 10;
BA_ "GenMsgCycleTime" BO_ 146 1;
BA_ "GenMsgCycleTime" BO_ 408 100;
BA_ "GenMsgCycleTime" BO_ 411 100;
BA_ "GenMsgCycleTime" BO_ 131 10;
BA_ "GenMsgCycleTime" BO_ 160 10;
BA_ "GenMsgCycleTime" BO_ 161 10;
BA_ "GenMsgCycleTime" BO_ 162 10;
BA_ "GenMsgCycleTime" BO_ 163 10;
BA_ "GenMsgCycleTime" BO_ 164 10;
BA_ "GenMsgCycleTime" BO_ 400 10;
BA_ "GenMsgCycleTime" BO_ 401 10;
BA_ "GenMsgCycleTime" BO_ 402 10;
BA_ "GenMsgCycleTime" BO_ 403 10;
BA_ "GenMsgCycleTime" BO_ 404 10;
BA_ "GenMsgCycleTime" BO_ 187 10;
BA_ "GenMsgCycleTime" BO_ 188 10;
BA_ "GenSigStartValue" SG_ 414 HB_TargetTemp_RR1 80;
BA_ "GenSigStartValue" SG_ 414 HB_ActualTemp_RR1 80;
BA_ "GenSigStartValue" SG_ 413 HB_TargetTemp_RL2 80;
BA_ "GenSigStartValue" SG_ 413 HB_ActualTemp_RL2 80;
BA_ "GenSigStartValue" SG_ 412 HB_TargetTemp_RL1 80;
BA_ "GenSigStartValue" SG_ 412 HB_ActualTemp_RL1 80;
BA_ "GenSigStartValue" SG_ 411 HB_TargetTemp_FR 80;
BA_ "GenSigStartValue" SG_ 411 HB_ActualTemp_FR 80;
VAL_ 371 SEAL_RL2_ActivationStatus 2 "deflate" 1 "inflate" 0 "ready" ;
VAL_ 184 OMS_State_CapSensor 1 "available" 0 "not available" ;
VAL_ 184 OMS_State_StrainGauge 1 "available" 0 "not available" ;
VAL_ 184 OMS_State_Camera 1 "available" 0 "not available" ;
VAL_ 132 HMI_SensorFusion_CapSensor 1 "requested" 0 "not requested" ;
VAL_ 132 HMI_SensorFusion_StrainGage 1 "requested" 0 "not requested" ;
VAL_ 132 HMI_SensorFusion_Camera 1 "requested" 0 "not requested" ;
VAL_ 513 ECU_PowerRequest_Jetson 1 "Shutdown" 0 "Power On (default)" ;
VAL_ 129 HMI_SEAL_ActivationRequest 1 "request for inflate" 0 "request for exflate (default)" ;
VAL_ 409 BSW_RR1_BuckleStatus 1 "Buckled" 0 "Unbuckled" ;
VAL_ 409 BSW_RL2_BuckleStatus 1 "Buckled" 0 "Unbuckled" ;
VAL_ 409 BSW_RL1_BuckleStatus 1 "Buckled" 0 "Unbuckled" ;
VAL_ 409 BSW_FR_BuckleStatus 1 "Buckled" 0 "Unbuckled" ;
VAL_ 409 BSW_FL_BuckleStatus 1 "Buckled" 0 "Unbuckled" ;
VAL_ 146 ELK_ResetErrorFlags 1 "reset error counters" 0 "nothing" ;
VAL_ 146 ELK_FL_LockingRequest 1 "Request for lock" 0 "No lock" ;
VAL_ 146 ELK_FR_LockingRequest 1 "Request for lock" 0 "No lock" ;
VAL_ 146 ELK_RR1_LockingRequest 1 "Request for lock" 0 "No lock" ;
VAL_ 146 ELK_RL2_LockingRequest 1 "Request for lock" 0 "No lock" ;
VAL_ 146 ELK_RL1_LockingRequest 1 "Request for lock" 0 "No lock" ;
VAL_ 408 ELK_RR1_ActuatorStatus 2 "Failure detected" 1 "Failure in previous cycle" 0 "No failure" ;
VAL_ 408 ELK_RL2_ActuatorStatus 2 "Failure detected" 1 "Failure in previous cycle" 0 "No failure" ;
VAL_ 408 ELK_RL1_ActuatorStatus 2 "Failure detected" 1 "Failure in previous cycle" 0 "No failure" ;
VAL_ 408 ELK_FR_ActuatorStatus 2 "Failure detected" 1 "Failure in previous cycle" 0 "No failure" ;
VAL_ 408 ELK_FL_ActuatorStatus 2 "Failure detected" 1 "Failure in previous cycle" 0 "No failure" ;
VAL_ 408 ELK_RR1_LockingStatus 1 "locked" 0 "unlocked" ;
VAL_ 408 ELK_RL2_LockingStatus 1 "locked" 0 "unlocked" ;
VAL_ 408 ELK_RL1_LockingStatus 1 "locked" 0 "unlocked" ;
VAL_ 408 ELK_FR_LockingStatus 1 "locked" 0 "unlocked" ;
VAL_ 408 ELK_FL_LockingStatus 1 "locked" 0 "unlocked" ;
